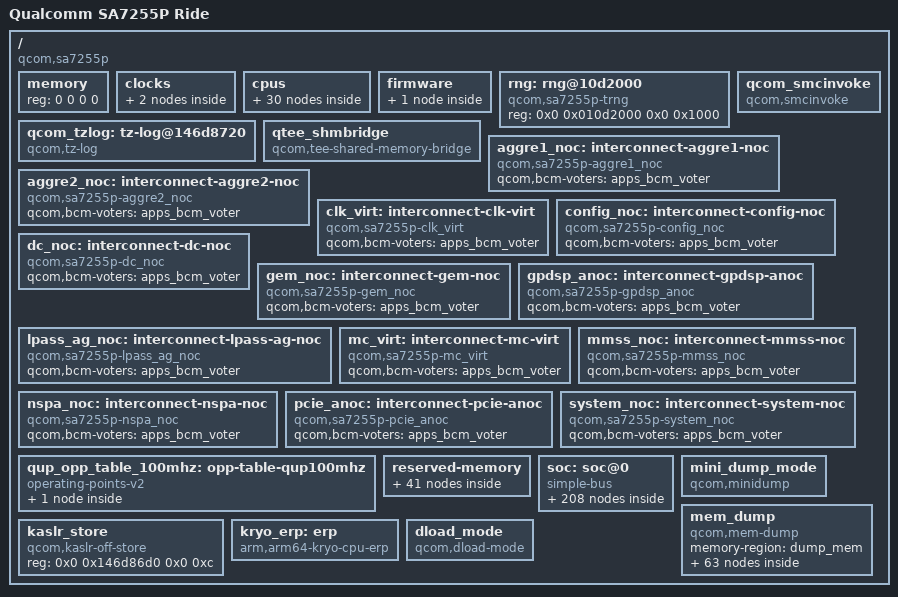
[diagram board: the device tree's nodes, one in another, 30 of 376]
// SPDX-License-Identifier: BSD-3-Clause
/*
 * Copyright (c) 2024 Qualcomm Innovation Center, Inc. All rights reserved.
 */

#include <dt-bindings/interrupt-controller/arm-gic.h>
#include <dt-bindings/clock/qcom,rpmh.h>
#include <dt-bindings/clock/qcom,camcc-sa8775p.h>
#include <dt-bindings/clock/qcom,sa7255p-dispcc.h>
#include <dt-bindings/clock/qcom,sa7255p-gcc.h>
#include <dt-bindings/clock/qcom,sa8775p-gpucc.h>
#include <dt-bindings/clock/qcom,videocc-sa8775p.h>
#include <dt-bindings/interconnect/qcom,sa7255p-rpmh.h>
#include <dt-bindings/interconnect/qcom,icc.h>
#include <dt-bindings/power/qcom-rpmpd.h>
#include <dt-bindings/soc/qcom,rpmh-rsc.h>
#include <oot-dt-bindings/qcom-ipcc.h>

/ {
	model = "Qualcomm SA7255P Ride";
	compatible = "qcom,sa7255p";
	interrupt-parent = <&intc>;

	#address-cells = <2>;
	#size-cells = <2>;

	memory { device_type = "memory"; reg = <0 0 0 0>; };

	clocks {
		xo_board_clk: xo-board-clk {
			compatible = "fixed-clock";
			#clock-cells = <0>;
		};

		sleep_clk: sleep-clk {
			compatible = "fixed-clock";
			#clock-cells = <0>;
		};
	};

	cpus {
		#address-cells = <2>;
		#size-cells = <0>;

		CPU0: cpu@0 {
			device_type = "cpu";
			compatible = "qcom,kryo";
			reg = <0x0 0x0>;
			enable-method = "psci";
			next-level-cache = <&L2_0>;
			L2_0: l2-cache {
			      compatible = "arm,arch-cache";
			      cache-level = <2>;
			      next-level-cache = <&L3_0>;

				L3_0: l3-cache {
				      compatible = "arm,arch-cache";
				      cache-level = <3>;
				};
			};
		};

		CPU1: cpu@100 {
			device_type = "cpu";
			compatible = "qcom,kryo";
			reg = <0x0 0x100>;
			enable-method = "psci";
			next-level-cache = <&L2_1>;
			L2_1: l2-cache {
			      compatible = "arm,arch-cache";
			      cache-level = <2>;
			      next-level-cache = <&L3_0>;
			};
		};

		CPU2: cpu@200 {
			device_type = "cpu";
			compatible = "qcom,kryo";
			reg = <0x0 0x200>;
			enable-method = "psci";
			next-level-cache = <&L2_2>;
			L2_2: l2-cache {
			      compatible = "arm,arch-cache";
			      cache-level = <2>;
			      next-level-cache = <&L3_0>;
			};
		};

		CPU3: cpu@300 {
			device_type = "cpu";
			compatible = "qcom,kryo";
			reg = <0x0 0x300>;
			enable-method = "psci";
			next-level-cache = <&L2_3>;
			L2_3: l2-cache {
			      compatible = "arm,arch-cache";
			      cache-level = <2>;
			      next-level-cache = <&L3_0>;
			};
		};

		CPU4: cpu@10000 {
			device_type = "cpu";
			compatible = "qcom,kryo";
			reg = <0x0 0x10000>;
			enable-method = "psci";
			next-level-cache = <&L2_4>;
			L2_4: l2-cache {
			      compatible = "arm,arch-cache";
			      cache-level = <2>;
			      next-level-cache = <&L3_1>;
				L3_1: l3-cache {
				      compatible = "arm,arch-cache";
				      cache-level = <3>;
				};
			};
		};

		CPU5: cpu@10100 {
			device_type = "cpu";
			compatible = "qcom,kryo";
			reg = <0x0 0x10100>;
			enable-method = "psci";
			next-level-cache = <&L2_5>;
			L2_5: l2-cache {
			      compatible = "arm,arch-cache";
			      cache-level = <2>;
			      next-level-cache = <&L3_1>;
			};
		};

		CPU6: cpu@10200 {
			device_type = "cpu";
			compatible = "qcom,kryo";
			reg = <0x0 0x10200>;
			enable-method = "psci";
			next-level-cache = <&L2_6>;
			L2_6: l2-cache {
			      compatible = "arm,arch-cache";
			      cache-level = <2>;
			      next-level-cache = <&L3_1>;
			};
		};

		CPU7: cpu@10300 {
			device_type = "cpu";
			compatible = "qcom,kryo";
			reg = <0x0 0x10300>;
			enable-method = "psci";
			next-level-cache = <&L2_7>;
			L2_7: l2-cache {
			      compatible = "arm,arch-cache";
			      cache-level = <2>;
			      next-level-cache = <&L3_1>;
			};
		};

		cpu-map {
			cluster0 {
				core0 {
					cpu = <&CPU0>;
				};

				core1 {
					cpu = <&CPU1>;
				};
			};

			cluster1 {
				core0 {
					cpu = <&CPU2>;
				};

				core1 {
					cpu = <&CPU3>;
				};
			};

			cluster2 {
				core0 {
					cpu = <&CPU4>;
				};

				core1 {
					cpu = <&CPU5>;
				};

				core2 {
					cpu = <&CPU6>;
				};

				core3 {
					cpu = <&CPU7>;
				};
			};
		};
	};

	firmware {
		qcom_scm {
			compatible = "qcom,scm";
			qcom,dload-mode = <&tcsr 0x13000>;
		};
	};

	rng: rng@10d2000 {
		compatible = "qcom,sa7255p-trng", "qcom,trng";
		reg = <0x0 0x010d2000 0x0 0x1000>;
	};

	qcom_tzlog: tz-log@146d8720 {
		compatible = "qcom,tz-log";
		reg = <0x0 0x146d8720 0x0 0x3000>;
		qcom,hyplog-enabled;
		hyplog-address-offset = <0x410>;
		hyplog-size-offset = <0x414>;
	};

	qtee_shmbridge {
		compatible = "qcom,tee-shared-memory-bridge";
		qcom,support-hypervisor;
		memory-region = <&cma>;
	};

	qcom_smcinvoke {
		compatible = "qcom,smcinvoke";
	};

	aggre1_noc: interconnect-aggre1-noc {
		compatible = "qcom,sa7255p-aggre1_noc";
		#interconnect-cells = <2>;
		qcom,bcm-voters = <&apps_bcm_voter>;
	};

	aggre2_noc: interconnect-aggre2-noc {
		compatible = "qcom,sa7255p-aggre2_noc";
		#interconnect-cells = <2>;
		qcom,bcm-voters = <&apps_bcm_voter>;
	};

	clk_virt: interconnect-clk-virt {
		compatible = "qcom,sa7255p-clk_virt";
		#interconnect-cells = <2>;
		qcom,bcm-voters = <&apps_bcm_voter>;
	};

	config_noc: interconnect-config-noc {
		compatible = "qcom,sa7255p-config_noc";
		#interconnect-cells = <2>;
		qcom,bcm-voters = <&apps_bcm_voter>;
	};

	dc_noc: interconnect-dc-noc {
		compatible = "qcom,sa7255p-dc_noc";
		#interconnect-cells = <2>;
		qcom,bcm-voters = <&apps_bcm_voter>;
	};

	gem_noc: interconnect-gem-noc {
		compatible = "qcom,sa7255p-gem_noc";
		#interconnect-cells = <2>;
		qcom,bcm-voters = <&apps_bcm_voter>;
	};

	gpdsp_anoc: interconnect-gpdsp-anoc {
		compatible = "qcom,sa7255p-gpdsp_anoc";
		#interconnect-cells = <2>;
		qcom,bcm-voters = <&apps_bcm_voter>;
	};

	lpass_ag_noc: interconnect-lpass-ag-noc {
		compatible = "qcom,sa7255p-lpass_ag_noc";
		#interconnect-cells = <2>;
		qcom,bcm-voters = <&apps_bcm_voter>;
	};

	mc_virt: interconnect-mc-virt {
		compatible = "qcom,sa7255p-mc_virt";
		#interconnect-cells = <2>;
		qcom,bcm-voters = <&apps_bcm_voter>;
	};

	mmss_noc: interconnect-mmss-noc {
		compatible = "qcom,sa7255p-mmss_noc";
		#interconnect-cells = <2>;
		qcom,bcm-voters = <&apps_bcm_voter>;
	};

	nspa_noc: interconnect-nspa-noc {
		compatible = "qcom,sa7255p-nspa_noc";
		#interconnect-cells = <2>;
		qcom,bcm-voters = <&apps_bcm_voter>;
	};

	pcie_anoc: interconnect-pcie-anoc {
		compatible = "qcom,sa7255p-pcie_anoc";
		#interconnect-cells = <2>;
		qcom,bcm-voters = <&apps_bcm_voter>;
	};

	system_noc: interconnect-system-noc {
		compatible = "qcom,sa7255p-system_noc";
		#interconnect-cells = <2>;
		qcom,bcm-voters = <&apps_bcm_voter>;
	};

	qup_opp_table_100mhz: opp-table-qup100mhz {
		compatible = "operating-points-v2";

		opp-100000000 {
			opp-hz = /bits/ 64 <100000000>;
			required-opps = <&rpmhpd_opp_svs_l1>;
		};
	};

	reserved-memory {
		#address-cells = <2>;
		#size-cells = <2>;
		ranges;

		sail_ss_mem: sail_ss_region@80000000 {
			no-map;
			reg = <0x0 0x80000000 0x0 0x10000000>;
		};

		hyp_mem: hyp_region@90000000 {
			no-map;
			reg = <0x0 0x90000000 0x0 0x600000>;
		};

		xbl_boot_mem: xbl_boot_region@90700000 {
			no-map;
			reg = <0x0 0x90700000 0x0 0x100000>;
		};

		aop_image_mem: aop_image_region@90800000 {
			no-map;
			reg = <0x0 0x90800000 0x0 0x60000>;
		};

		aop_cmd_db_mem: aop_cmd_db_region@90860000 {
			compatible = "qcom,cmd-db";
			no-map;
			reg = <0x0 0x90860000 0x0 0x20000>;
		};

		uefi_xbl_logs_mem: uefi_xbl_logs_region@908b0000 {
			no-map;
			reg = <0x0 0x908b0000 0x0 0x10000>;
		};

		ddr_training_cksum_data_mem: ddr_training_cksum_data_region@908c0000 {
			no-map;
			reg = <0x0 0x908c0000 0x0 0x1000>;
		};

		reserved_mem: reserved_region@908f0000 {
			no-map;
			reg = <0x0 0x908f0000 0x0 0xe000>;
		};

		secdata_apss_mem: secdata_apss_region@908fe000 {
			no-map;
			reg = <0x0 0x908fe000 0x0 0x2000>;
		};

		secboot_emulation_mem: secboot_emulation_region@908fe000 {
			no-map;
			reg = <0x0 0x908fe000 0x0 0x1000>;
		};

		smem_mem: smem@90900000 {
			compatible = "qcom,smem";
			reg = <0x0 0x90900000 0x0 0x200000>;
			no-map;
			hwlocks = <&tcsr_mutex 3>;
		};


		tz_sail_mailbox_mem: tz_sail_mailbox_region@90c00000 {
			no-map;
			reg = <0x0 0x90c00000 0x0 0x100000>;
		};

		hlos_sail_mailbox_mem: hlos_sail_mailbox_region@90d00000 {
			no-map;
			reg = <0x0 0x90d00000 0x0 0x100000>;
		};

		sail_ota_mem: sail_ota_region@90e00000 {
			no-map;
			reg = <0x0 0x90e00000 0x0 0x300000>;
		};

		aoss_backup_mem: aoss_backup_region@91b00000 {
			no-map;
			reg = <0x0 0x91b00000 0x0 0x40000>;
		};

		cpucp_backup_mem: cpucp_backup_region@91b40000 {
			no-map;
			reg = <0x0 0x91b40000 0x0 0x40000>;
		};

		tz_config_backup_mem: tz_config_backup_region@91b80000 {
			no-map;
			reg = <0x0 0x91b80000 0x0 0x10000>;
		};

		ddr_training_data_mem: ddr_training_data_region@91b90000 {
			no-map;
			reg = <0x0 0x91b90000 0x0 0x10000>;
		};

		cdt_data_backup_mem: cdt_data_backup_region@91ba0000 {
			no-map;
			reg = <0x0 0x91ba0000 0x0 0x1000>;
		};

		lpass_machine_learning_mem: lpass_machine_learning_region@93b00000 {
			no-map;
			reg = <0x0 0x93b00000 0x0 0xf00000>;
		};

		adsp_rpc_remote_heap_mem: adsp_rpc_remote_heap_region@94a00000 {
			no-map;
			reg = <0x0 0x94a00000 0x0 0x800000>;
		};

		camera_mem: camera_region@95200000 {
			no-map;
			reg = <0x0 0x95200000 0x0 0x500000>;
		};

		mproc_umdpil_mem: mproc_umdpil_region@95700000 {
			no-map;
			reg = <0x0 0x95700000 0x0 0x500000>;
		};

		adsp_mem: adsp_region@95c00000 {
			no-map;
			reg = <0x0 0x95c00000 0x0 0x1e00000>;
		};

		gpdsp_mem: gpdsp_region@97b00000 {
			no-map;
			reg = <0x0 0x97b00000 0x0 0x1e00000>;
		};

		cdsp_mem: cdsp_region@99980000 {
			no-map;
			reg = <0x0 0x99980000 0x0 0x1e00000>;
		};

		gpu_microcode_mem: gpu_microcode_region@9b780000 {
			no-map;
			reg = <0x0 0x9b780000 0x0 0x2000>;
		};

		cvp_mem: cvp_region@9b782000 {
			no-map;
			reg = <0x0 0x9b782000 0x0 0x700000>;
		};

		video_mem: video_region@9be82000 {
			no-map;
			reg = <0x0 0x9be82000 0x0 0x700000>;
		};

		hyp_logging_mem: hyp_logging_region@beb00000 {
			no-map;
			reg = <0x0 0xbeb00000 0x0 0x2000000>;
		};

		heap_mem: heap_region@c0b00000 {
			no-map;
			reg = <0x0 0xc0b00000 0x0 0x400000>;
		};

		tags_mem: tags_region@d0100000 {
			no-map;
			reg = <0x0 0xd0100000 0x0 0x800000>;
		};

		pimem_vault_1_mem: pimem_vault_1_region@d0900000 {
			no-map;
			reg = <0x0 0xd0900000 0x0 0xa00000>;
		};

		qtee_mem: qtee_region@d1300000 {
			no-map;
			reg = <0x0 0xd1300000 0x0 0x500000>;
		};

		deep_sleep_back_up_mem: deep_sleep_back_up_region@d1800000 {
			no-map;
			reg = <0x0 0xd1800000 0x0 0x100000>;
		};

		trusted_apps_mem: trusted_apps_region@d1900000 {
			no-map;
			reg = <0x0 0xd1900000 0x0 0x1900000>;
		};

		pimem_vault_2_mem: pimem_vault_2_region@d3200000 {
			no-map;
			reg = <0x0 0xd3200000 0x0 0x100000>;
		};

		tz_stat_mem: tz_stat_region@db100000 {
			no-map;
			reg = <0x0 0xdb100000 0x0 0x100000>;
		};

		cpucp_fw_mem: cpucp_fw_region@db200000 {
			no-map;
			reg = <0x0 0xdb200000 0x0 0x100000>;
		};

		/* global autoconfigured region for contiguous allocations */
		cma: linux,cma {
			compatible = "shared-dma-pool";
			alloc-ranges = <0x0 0x00000000 0x0 0xffffffff>;
			reusable;
			alignment = <0x0 0x400000>;
			size = <0x0 0x2000000>;
			linux,cma-default;
		};

		dump_mem: mem_dump_region {
			alloc-ranges = <0x0 0x00000000 0x0 0xffffffff>;
			compatible = "shared-dma-pool";
			reusable;
			size = <0x0 0x3000000>;
		};
	};

	soc: soc@0 {
		#address-cells = <2>;
		#size-cells = <2>;
		ranges = <0 0 0 0 0x10 0>;
		compatible = "simple-bus";

		gcc: clock-controller@100000 {
			compatible = "qcom,sa7255p-gcc";
			reg = <0x0 0x00100000 0x0 0xc7018>;
			#clock-cells = <1>;
			#reset-cells = <1>;
			#power-domain-cells = <1>;
			clocks = <&rpmhcc RPMH_CXO_CLK>,
				 <&sleep_clk>,
				 <0>,
				 <0>,
				 <0>,
				 <&usb_0_qmpphy>,
				 <0>,
				 <0>,
				 <0>,
				 <0>;
			power-domains = <&rpmhpd SA7255P_CX>;
		};

		gpucc: clock-controller@3d90000 {
			compatible = "qcom,sa7255p-gpucc";
			reg = <0x0 0x03d90000 0x0 0xa000>;
			clocks = <&rpmhcc RPMH_CXO_CLK>,
				 <&gcc GCC_GPU_GPLL0_CLK_SRC>,
				 <&gcc GCC_GPU_GPLL0_DIV_CLK_SRC>;
			clock-names = "bi_tcxo",
				      "gcc_gpu_gpll0_clk_src",
				      "gcc_gpu_gpll0_div_clk_src";
			#clock-cells = <1>;
			#reset-cells = <1>;
			#power-domain-cells = <1>;
		};

		videocc: clock-controller@abf0000 {
			compatible = "qcom,sa7255p-videocc";
			reg = <0x0 0xabf0000 0x0 0x10000>;
			clocks = <&gcc GCC_VIDEO_AHB_CLK>,
				 <&rpmhcc RPMH_CXO_CLK>,
				 <&rpmhcc RPMH_CXO_CLK_A>,
				 <&sleep_clk>;
			power-domains = <&rpmhpd SA7255P_MMCX>;
			required-opps = <&rpmhpd_opp_nom>;
			#clock-cells = <1>;
			#reset-cells = <1>;
			#power-domain-cells = <1>;
		};

		camcc: clock-controller@ade0000 {
			compatible = "qcom,sa7255p-camcc";
			reg = <0x0 0xade0000 0x0 0x20000>;
			clocks = <&gcc GCC_CAMERA_AHB_CLK>,
				 <&rpmhcc RPMH_CXO_CLK>,
				 <&rpmhcc RPMH_CXO_CLK_A>,
				 <&sleep_clk>;
			power-domains = <&rpmhpd SA7255P_MMCX>;
			required-opps = <&rpmhpd_opp_nom>;
			#clock-cells = <1>;
			#reset-cells = <1>;
			#power-domain-cells = <1>;
		};

		dispcc: clock-controller@af00000 {
			compatible = "qcom,sa7255p-dispcc";
			reg = <0x0 0xaf00000 0x0 0x20000>;
			clocks = <&gcc GCC_DISP_AHB_CLK>,
				 <&rpmhcc RPMH_CXO_CLK>,
				 <&rpmhcc RPMH_CXO_CLK_A>,
				 <&sleep_clk>,
				 <0>,
				 <0>,
				 <0>,
				 <0>,
				 <0>,
				 <0>,
				 <0>,
				 <0>;
			power-domains = <&rpmhpd SA7255P_MMCX>;
			required-opps = <&rpmhpd_opp_nom>;
			#clock-cells = <1>;
			#reset-cells = <1>;
			#power-domain-cells = <1>;
		};

		dummy_proxy_votes: dummy-proxy-votes {
			compatible = "qcom,sa7255p-dummy";
			power-domains = <&rpmhpd SA7255P_NSP0>,
					<&rpmhpd SA7255P_NSP1>;
		};

		qupv3_id_0: geniqup@9c0000 {
			compatible = "qcom,geni-se-qup";
			reg = <0x0 0x9c0000 0x0 0x2000>;
			#address-cells = <2>;
			#size-cells = <2>;
			ranges;
			clock-names = "m-ahb", "s-ahb";
			clocks = <&gcc GCC_QUPV3_WRAP_0_M_AHB_CLK>,
				<&gcc GCC_QUPV3_WRAP_0_S_AHB_CLK>;
			iommus = <&apps_smmu 0x403 0x0>;
			status = "disabled";

			i2c0: i2c@980000 {
				compatible = "qcom,geni-i2c";
				reg = <0x0 0x980000 0x0 0x4000>;
				#address-cells = <1>;
				#size-cells = <0>;
				interrupts = <GIC_SPI 550 IRQ_TYPE_LEVEL_HIGH>;
				clocks = <&gcc GCC_QUPV3_WRAP0_S0_CLK>;
				clock-names = "se";
				interconnects = <&clk_virt MASTER_QUP_CORE_0 QCOM_ICC_TAG_ALWAYS
						 &clk_virt SLAVE_QUP_CORE_0 QCOM_ICC_TAG_ALWAYS>,
						<&gem_noc MASTER_APPSS_PROC QCOM_ICC_TAG_ALWAYS
						 &config_noc SLAVE_QUP_0 QCOM_ICC_TAG_ALWAYS>,
						<&aggre2_noc MASTER_QUP_0 QCOM_ICC_TAG_ALWAYS
						 &mc_virt SLAVE_EBI1 QCOM_ICC_TAG_ALWAYS>;
				interconnect-names = "qup-core",
						     "qup-config",
						     "qup-memory";
				power-domains = <&rpmhpd SA7255P_CX>;
				status = "disabled";
			};

			i2c1: i2c@984000 {
				compatible = "qcom,geni-i2c";
				reg = <0x0 0x984000 0x0 0x4000>;
				#address-cells = <1>;
				#size-cells = <0>;
				interrupts = <GIC_SPI 551 IRQ_TYPE_LEVEL_HIGH>;
				clocks = <&gcc GCC_QUPV3_WRAP0_S1_CLK>;
				clock-names = "se";
				interconnects = <&clk_virt MASTER_QUP_CORE_0 QCOM_ICC_TAG_ALWAYS
						 &clk_virt SLAVE_QUP_CORE_0 QCOM_ICC_TAG_ALWAYS>,
						<&gem_noc MASTER_APPSS_PROC QCOM_ICC_TAG_ALWAYS
						 &config_noc SLAVE_QUP_0 QCOM_ICC_TAG_ALWAYS>,
						<&aggre2_noc MASTER_QUP_0 QCOM_ICC_TAG_ALWAYS
						 &mc_virt SLAVE_EBI1 QCOM_ICC_TAG_ALWAYS>;
				interconnect-names = "qup-core",
						     "qup-config",
						     "qup-memory";
				power-domains = <&rpmhpd SA7255P_CX>;
				status = "disabled";
			};

			i2c2: i2c@988000 {
				compatible = "qcom,geni-i2c";
				reg = <0x0 0x988000 0x0 0x4000>;
				#address-cells = <1>;
				#size-cells = <0>;
				interrupts = <GIC_SPI 529 IRQ_TYPE_LEVEL_HIGH>;
				clocks = <&gcc GCC_QUPV3_WRAP0_S2_CLK>;
				clock-names = "se";
				interconnects = <&clk_virt MASTER_QUP_CORE_0 QCOM_ICC_TAG_ALWAYS
						 &clk_virt SLAVE_QUP_CORE_0 QCOM_ICC_TAG_ALWAYS>,
						<&gem_noc MASTER_APPSS_PROC QCOM_ICC_TAG_ALWAYS
						 &config_noc SLAVE_QUP_0 QCOM_ICC_TAG_ALWAYS>,
						<&aggre2_noc MASTER_QUP_0 QCOM_ICC_TAG_ALWAYS
						 &mc_virt SLAVE_EBI1 QCOM_ICC_TAG_ALWAYS>;
				interconnect-names = "qup-core",
						     "qup-config",
						     "qup-memory";
				power-domains = <&rpmhpd SA7255P_CX>;
				status = "disabled";
			};

			spi2: spi@988000 {
				compatible = "qcom,geni-spi";
				reg = <0x0 0x988000 0x0 0x4000>;
				#address-cells = <1>;
				#size-cells = <0>;
				interrupts = <GIC_SPI 529 IRQ_TYPE_LEVEL_HIGH>;
				clocks = <&gcc GCC_QUPV3_WRAP0_S2_CLK>;
				clock-names = "se";
				interconnects = <&clk_virt MASTER_QUP_CORE_0 QCOM_ICC_TAG_ALWAYS
						 &clk_virt SLAVE_QUP_CORE_0 QCOM_ICC_TAG_ALWAYS>,
						<&gem_noc MASTER_APPSS_PROC QCOM_ICC_TAG_ALWAYS
						 &config_noc SLAVE_QUP_0 QCOM_ICC_TAG_ALWAYS>,
						<&aggre2_noc MASTER_QUP_0 QCOM_ICC_TAG_ALWAYS
						 &mc_virt SLAVE_EBI1 QCOM_ICC_TAG_ALWAYS>;
				interconnect-names = "qup-core",
						     "qup-config",
						     "qup-memory";
				power-domains = <&rpmhpd SA7255P_CX>;
				status = "disabled";
			};

			uart2: serial@988000 {
				compatible = "qcom,geni-uart";
				reg = <0x0 0x988000 0x0 0x4000>;
				interrupts = <GIC_SPI 529 IRQ_TYPE_LEVEL_HIGH>;
				clocks = <&gcc GCC_QUPV3_WRAP0_S2_CLK>;
				clock-names = "se";
				interconnects = <&clk_virt MASTER_QUP_CORE_0 QCOM_ICC_TAG_ALWAYS
						 &clk_virt SLAVE_QUP_CORE_0 QCOM_ICC_TAG_ALWAYS>,
						<&gem_noc MASTER_APPSS_PROC QCOM_ICC_TAG_ALWAYS
						 &config_noc SLAVE_QUP_0 QCOM_ICC_TAG_ALWAYS>;
				interconnect-names = "qup-core", "qup-config";
				power-domains = <&rpmhpd SA7255P_CX>;
				status = "disabled";
			};

			i2c3: i2c@98c000 {
				compatible = "qcom,geni-i2c";
				reg = <0x0 0x98c000 0x0 0x4000>;
				#address-cells = <1>;
				#size-cells = <0>;
				interrupts = <GIC_SPI 530 IRQ_TYPE_LEVEL_HIGH>;
				clocks = <&gcc GCC_QUPV3_WRAP0_S3_CLK>;
				clock-names = "se";
				interconnects = <&clk_virt MASTER_QUP_CORE_0 QCOM_ICC_TAG_ALWAYS
						 &clk_virt SLAVE_QUP_CORE_0 QCOM_ICC_TAG_ALWAYS>,
						<&gem_noc MASTER_APPSS_PROC QCOM_ICC_TAG_ALWAYS
						 &config_noc SLAVE_QUP_0 QCOM_ICC_TAG_ALWAYS>,
						<&aggre2_noc MASTER_QUP_0 QCOM_ICC_TAG_ALWAYS
						 &mc_virt SLAVE_EBI1 QCOM_ICC_TAG_ALWAYS>;
				interconnect-names = "qup-core",
						     "qup-config",
						     "qup-memory";
				power-domains = <&rpmhpd SA7255P_CX>;
				status = "disabled";
			};

			spi3: spi@98c000 {
				compatible = "qcom,geni-spi";
				reg = <0x0 0x98c000 0x0 0x4000>;
				#address-cells = <1>;
				#size-cells = <0>;
				interrupts = <GIC_SPI 530 IRQ_TYPE_LEVEL_HIGH>;
				clocks = <&gcc GCC_QUPV3_WRAP0_S3_CLK>;
				clock-names = "se";
				interconnects = <&clk_virt MASTER_QUP_CORE_0 QCOM_ICC_TAG_ALWAYS
						 &clk_virt SLAVE_QUP_CORE_0 QCOM_ICC_TAG_ALWAYS>,
						<&gem_noc MASTER_APPSS_PROC QCOM_ICC_TAG_ALWAYS
						 &config_noc SLAVE_QUP_0 QCOM_ICC_TAG_ALWAYS>,
						<&aggre2_noc MASTER_QUP_0 QCOM_ICC_TAG_ALWAYS
						 &mc_virt SLAVE_EBI1 QCOM_ICC_TAG_ALWAYS>;
				interconnect-names = "qup-core",
						     "qup-config",
						     "qup-memory";
				power-domains = <&rpmhpd SA7255P_CX>;
				status = "disabled";
			};

			uart3: serial@98c000 {
				compatible = "qcom,geni-uart";
				reg = <0x0 0x98c000 0x0 0x4000>;
				interrupts = <GIC_SPI 530 IRQ_TYPE_LEVEL_HIGH>;
				clocks = <&gcc GCC_QUPV3_WRAP0_S3_CLK>;
				clock-names = "se";
				interconnects = <&clk_virt MASTER_QUP_CORE_0 QCOM_ICC_TAG_ALWAYS
						 &clk_virt SLAVE_QUP_CORE_0 QCOM_ICC_TAG_ALWAYS>,
						<&gem_noc MASTER_APPSS_PROC QCOM_ICC_TAG_ALWAYS
						 &config_noc SLAVE_QUP_0 QCOM_ICC_TAG_ALWAYS>;
				interconnect-names = "qup-core", "qup-config";
				power-domains = <&rpmhpd SA7255P_CX>;
				status = "disabled";
			};

			i2c4: i2c@990000 {
				compatible = "qcom,geni-i2c";
				reg = <0x0 0x990000 0x0 0x4000>;
				#address-cells = <1>;
				#size-cells = <0>;
				interrupts = <GIC_SPI 531 IRQ_TYPE_LEVEL_HIGH>;
				clocks = <&gcc GCC_QUPV3_WRAP0_S4_CLK>;
				clock-names = "se";
				interconnects = <&clk_virt MASTER_QUP_CORE_0 QCOM_ICC_TAG_ALWAYS
						 &clk_virt SLAVE_QUP_CORE_0 QCOM_ICC_TAG_ALWAYS>,
						<&gem_noc MASTER_APPSS_PROC QCOM_ICC_TAG_ALWAYS
						 &config_noc SLAVE_QUP_0 QCOM_ICC_TAG_ALWAYS>,
						<&aggre2_noc MASTER_QUP_0 QCOM_ICC_TAG_ALWAYS
						 &mc_virt SLAVE_EBI1 QCOM_ICC_TAG_ALWAYS>;
				interconnect-names = "qup-core",
						     "qup-config",
						     "qup-memory";
				power-domains = <&rpmhpd SA7255P_CX>;
				status = "disabled";
			};

			spi4: spi@990000 {
				compatible = "qcom,geni-spi";
				reg = <0x0 0x990000 0x0 0x4000>;
				#address-cells = <1>;
				#size-cells = <0>;
				interrupts = <GIC_SPI 531 IRQ_TYPE_LEVEL_HIGH>;
				clocks = <&gcc GCC_QUPV3_WRAP0_S4_CLK>;
				clock-names = "se";
				interconnects = <&clk_virt MASTER_QUP_CORE_0 QCOM_ICC_TAG_ALWAYS
						 &clk_virt SLAVE_QUP_CORE_0 QCOM_ICC_TAG_ALWAYS>,
						<&gem_noc MASTER_APPSS_PROC QCOM_ICC_TAG_ALWAYS
						 &config_noc SLAVE_QUP_0 QCOM_ICC_TAG_ALWAYS>,
						<&aggre2_noc MASTER_QUP_0 QCOM_ICC_TAG_ALWAYS
						 &mc_virt SLAVE_EBI1 QCOM_ICC_TAG_ALWAYS>;
				interconnect-names = "qup-core",
						     "qup-config",
						     "qup-memory";
				power-domains = <&rpmhpd SA7255P_CX>;
				status = "disabled";
			};

			i2c5: i2c@994000 {
				compatible = "qcom,geni-i2c";
				reg = <0x0 0x994000 0x0 0x4000>;
				#address-cells = <1>;
				#size-cells = <0>;
				interrupts = <GIC_SPI 535 IRQ_TYPE_LEVEL_HIGH>;
				clocks = <&gcc GCC_QUPV3_WRAP0_S5_CLK>;
				clock-names = "se";
				interconnects = <&clk_virt MASTER_QUP_CORE_0 QCOM_ICC_TAG_ALWAYS
						 &clk_virt SLAVE_QUP_CORE_0 QCOM_ICC_TAG_ALWAYS>,
						<&gem_noc MASTER_APPSS_PROC QCOM_ICC_TAG_ALWAYS
						 &config_noc SLAVE_QUP_0 QCOM_ICC_TAG_ALWAYS>,
						<&aggre2_noc MASTER_QUP_0 QCOM_ICC_TAG_ALWAYS
						 &mc_virt SLAVE_EBI1 QCOM_ICC_TAG_ALWAYS>;
				interconnect-names = "qup-core",
						     "qup-config",
						     "qup-memory";
				power-domains = <&rpmhpd SA7255P_CX>;
				status = "disabled";
			};

			spi5: spi@994000 {
				compatible = "qcom,geni-spi";
				reg = <0x0 0x994000 0x0 0x4000>;
				#address-cells = <1>;
				#size-cells = <0>;
				interrupts = <GIC_SPI 535 IRQ_TYPE_LEVEL_HIGH>;
				clocks = <&gcc GCC_QUPV3_WRAP0_S5_CLK>;
				clock-names = "se";
				interconnects = <&clk_virt MASTER_QUP_CORE_0 QCOM_ICC_TAG_ALWAYS
						 &clk_virt SLAVE_QUP_CORE_0 QCOM_ICC_TAG_ALWAYS>,
						<&gem_noc MASTER_APPSS_PROC QCOM_ICC_TAG_ALWAYS
						 &config_noc SLAVE_QUP_0 QCOM_ICC_TAG_ALWAYS>,
						<&aggre2_noc MASTER_QUP_0 QCOM_ICC_TAG_ALWAYS
						 &mc_virt SLAVE_EBI1 QCOM_ICC_TAG_ALWAYS>;
				interconnect-names = "qup-core",
						     "qup-config",
						     "qup-memory";
				power-domains = <&rpmhpd SA7255P_CX>;
				status = "disabled";
			};

			uart5: serial@994000 {
				compatible = "qcom,geni-uart";
				reg = <0x0 0x994000 0x0 0x4000>;
				interrupts = <GIC_SPI 535 IRQ_TYPE_LEVEL_HIGH>;
				clocks = <&gcc GCC_QUPV3_WRAP0_S5_CLK>;
				clock-names = "se";
				interconnects = <&clk_virt MASTER_QUP_CORE_0 QCOM_ICC_TAG_ALWAYS
						 &clk_virt SLAVE_QUP_CORE_0 QCOM_ICC_TAG_ALWAYS>,
						<&gem_noc MASTER_APPSS_PROC QCOM_ICC_TAG_ALWAYS
						 &config_noc SLAVE_QUP_0 QCOM_ICC_TAG_ALWAYS>;
				interconnect-names = "qup-core", "qup-config";
				power-domains = <&rpmhpd SA7255P_CX>;
				status = "disabled";
			};

			i2c6: i2c@998000 {
				compatible = "qcom,geni-i2c";
				reg = <0x0 0x998000 0x0 0x4000>;
				#address-cells = <1>;
				#size-cells = <0>;
				interrupts = <GIC_SPI 536 IRQ_TYPE_LEVEL_HIGH>;
				clocks = <&gcc GCC_QUPV3_WRAP0_S6_CLK>;
				clock-names = "se";
				interconnects = <&clk_virt MASTER_QUP_CORE_0 QCOM_ICC_TAG_ALWAYS
						 &clk_virt SLAVE_QUP_CORE_0 QCOM_ICC_TAG_ALWAYS>,
						<&gem_noc MASTER_APPSS_PROC QCOM_ICC_TAG_ALWAYS
						 &config_noc SLAVE_QUP_0 QCOM_ICC_TAG_ALWAYS>,
						<&aggre2_noc MASTER_QUP_0 QCOM_ICC_TAG_ALWAYS
						 &mc_virt SLAVE_EBI1 QCOM_ICC_TAG_ALWAYS>;
				interconnect-names = "qup-core",
						     "qup-config",
						     "qup-memory";
				power-domains = <&rpmhpd SA7255P_CX>;
				status = "disabled";
			};

			spi6: spi@998000 {
				compatible = "qcom,geni-spi";
				reg = <0x0 0x998000 0x0 0x4000>;
				#address-cells = <1>;
				#size-cells = <0>;
				interrupts = <GIC_SPI 536 IRQ_TYPE_LEVEL_HIGH>;
				clocks = <&gcc GCC_QUPV3_WRAP0_S6_CLK>;
				clock-names = "se";
				interconnects = <&clk_virt MASTER_QUP_CORE_0 QCOM_ICC_TAG_ALWAYS
						 &clk_virt SLAVE_QUP_CORE_0 QCOM_ICC_TAG_ALWAYS>,
						<&gem_noc MASTER_APPSS_PROC QCOM_ICC_TAG_ALWAYS
						 &config_noc SLAVE_QUP_0 QCOM_ICC_TAG_ALWAYS>,
						<&aggre2_noc MASTER_QUP_0 QCOM_ICC_TAG_ALWAYS
						 &mc_virt SLAVE_EBI1 QCOM_ICC_TAG_ALWAYS>;
				interconnect-names = "qup-core",
						     "qup-config",
						     "qup-memory";
				power-domains = <&rpmhpd SA7255P_CX>;
				status = "disabled";
			};

			uart7: serial@99c000 {
				compatible = "qcom,geni-uart";
				reg = <0x0 0x0099c000 0x0 0x4000>;
				interrupts = <GIC_SPI 126 IRQ_TYPE_LEVEL_HIGH>;
				clock-names = "se";
				clocks = <&gcc GCC_QUPV3_WRAP0_S7_CLK>;
				interconnect-names = "qup-core", "qup-config";
				interconnects = <&clk_virt MASTER_QUP_CORE_0 0
						 &clk_virt SLAVE_QUP_CORE_0 0>,
						<&gem_noc MASTER_APPSS_PROC 0
						 &config_noc SLAVE_QUP_0 0>;
				power-domains = <&rpmhpd SA7255P_CX>;
				operating-points-v2 = <&qup_opp_table_100mhz>;
				status = "disabled";
			};
		};

		qupv3_id_1: geniqup@ac0000 {
			compatible = "qcom,geni-se-qup";
			reg = <0x0 0x00ac0000 0x0 0x2000>;
			#address-cells = <2>;
			#size-cells = <2>;
			ranges;
			clock-names = "m-ahb", "s-ahb";
			clocks = <&gcc GCC_QUPV3_WRAP_1_M_AHB_CLK>,
				 <&gcc GCC_QUPV3_WRAP_1_S_AHB_CLK>;
			iommus = <&apps_smmu 0x443 0x0>;
			status = "disabled";

			i2c8: i2c@a80000 {
				compatible = "qcom,geni-i2c";
				reg = <0x0 0xa80000 0x0 0x4000>;
				#address-cells = <1>;
				#size-cells = <0>;
				interrupts = <GIC_SPI 353 IRQ_TYPE_LEVEL_HIGH>;
				clocks = <&gcc GCC_QUPV3_WRAP1_S0_CLK>;
				clock-names = "se";
				interconnects = <&clk_virt MASTER_QUP_CORE_1 QCOM_ICC_TAG_ALWAYS
						 &clk_virt SLAVE_QUP_CORE_1 QCOM_ICC_TAG_ALWAYS>,
						<&gem_noc MASTER_APPSS_PROC QCOM_ICC_TAG_ALWAYS
						 &config_noc SLAVE_QUP_1 QCOM_ICC_TAG_ALWAYS>,
						<&aggre2_noc MASTER_QUP_1 QCOM_ICC_TAG_ALWAYS
						 &mc_virt SLAVE_EBI1 QCOM_ICC_TAG_ALWAYS>;
				interconnect-names = "qup-core",
						     "qup-config",
						     "qup-memory";
				power-domains = <&rpmhpd SA7255P_CX>;
				status = "disabled";
			};

			i2c9: i2c@a84000 {
				compatible = "qcom,geni-i2c";
				reg = <0x0 0xa84000 0x0 0x4000>;
				#address-cells = <1>;
				#size-cells = <0>;
				interrupts = <GIC_SPI 354 IRQ_TYPE_LEVEL_HIGH>;
				clocks = <&gcc GCC_QUPV3_WRAP1_S1_CLK>;
				clock-names = "se";
				interconnects = <&clk_virt MASTER_QUP_CORE_1 QCOM_ICC_TAG_ALWAYS
						 &clk_virt SLAVE_QUP_CORE_1 QCOM_ICC_TAG_ALWAYS>,
						<&gem_noc MASTER_APPSS_PROC QCOM_ICC_TAG_ALWAYS
						 &config_noc SLAVE_QUP_1 QCOM_ICC_TAG_ALWAYS>,
						<&aggre2_noc MASTER_QUP_1 QCOM_ICC_TAG_ALWAYS
						 &mc_virt SLAVE_EBI1 QCOM_ICC_TAG_ALWAYS>;
				interconnect-names = "qup-core",
						     "qup-config",
						     "qup-memory";
				power-domains = <&rpmhpd SA7255P_CX>;
				status = "disabled";
			};

			i2c10: i2c@a88000 {
				compatible = "qcom,geni-i2c";
				reg = <0x0 0xa88000 0x0 0x4000>;
				#address-cells = <1>;
				#size-cells = <0>;
				interrupts = <GIC_SPI 355 IRQ_TYPE_LEVEL_HIGH>;
				clocks = <&gcc GCC_QUPV3_WRAP1_S2_CLK>;
				clock-names = "se";
				interconnects = <&clk_virt MASTER_QUP_CORE_1 QCOM_ICC_TAG_ALWAYS
						 &clk_virt SLAVE_QUP_CORE_1 QCOM_ICC_TAG_ALWAYS>,
						<&gem_noc MASTER_APPSS_PROC QCOM_ICC_TAG_ALWAYS
						 &config_noc SLAVE_QUP_1 QCOM_ICC_TAG_ALWAYS>,
						<&aggre2_noc MASTER_QUP_1 QCOM_ICC_TAG_ALWAYS
						 &mc_virt SLAVE_EBI1 QCOM_ICC_TAG_ALWAYS>;
				interconnect-names = "qup-core",
						     "qup-config",
						     "qup-memory";
				power-domains = <&rpmhpd SA7255P_CX>;
				status = "disabled";
			};

			spi10: spi@a88000 {
				compatible = "qcom,geni-spi";
				reg = <0x0 0xa88000 0x0 0x4000>;
				#address-cells = <1>;
				#size-cells = <0>;
				interrupts = <GIC_SPI 355 IRQ_TYPE_LEVEL_HIGH>;
				clocks = <&gcc GCC_QUPV3_WRAP1_S2_CLK>;
				clock-names = "se";
				interconnects = <&clk_virt MASTER_QUP_CORE_1 QCOM_ICC_TAG_ALWAYS
						 &clk_virt SLAVE_QUP_CORE_1 QCOM_ICC_TAG_ALWAYS>,
						<&gem_noc MASTER_APPSS_PROC QCOM_ICC_TAG_ALWAYS
						 &config_noc SLAVE_QUP_1 QCOM_ICC_TAG_ALWAYS>,
						<&aggre2_noc MASTER_QUP_1 QCOM_ICC_TAG_ALWAYS
						 &mc_virt SLAVE_EBI1 QCOM_ICC_TAG_ALWAYS>;
				interconnect-names = "qup-core",
						     "qup-config",
						     "qup-memory";
				power-domains = <&rpmhpd SA7255P_CX>;
				status = "disabled";
			};

			i2c11: i2c@a8c000 {
				compatible = "qcom,geni-i2c";
				reg = <0x0 0xa8c000 0x0 0x4000>;
				#address-cells = <1>;
				#size-cells = <0>;
				interrupts = <GIC_SPI 356 IRQ_TYPE_LEVEL_HIGH>;
				clocks = <&gcc GCC_QUPV3_WRAP1_S3_CLK>;
				clock-names = "se";
				interconnects = <&clk_virt MASTER_QUP_CORE_1 QCOM_ICC_TAG_ALWAYS
						 &clk_virt SLAVE_QUP_CORE_1 QCOM_ICC_TAG_ALWAYS>,
						<&gem_noc MASTER_APPSS_PROC QCOM_ICC_TAG_ALWAYS
						 &config_noc SLAVE_QUP_1 QCOM_ICC_TAG_ALWAYS>,
						<&aggre2_noc MASTER_QUP_1 QCOM_ICC_TAG_ALWAYS
						 &mc_virt SLAVE_EBI1 QCOM_ICC_TAG_ALWAYS>;
				interconnect-names = "qup-core",
						     "qup-config",
						     "qup-memory";
				power-domains = <&rpmhpd SA7255P_CX>;
				status = "disabled";
			};

			uart11: serial@a8c000 {
				compatible = "qcom,geni-uart";
				reg = <0x0 0xa8c000 0x0 0x4000>;
				interrupts = <GIC_SPI 356 IRQ_TYPE_LEVEL_HIGH>;
				clocks = <&gcc GCC_QUPV3_WRAP1_S3_CLK>;
				clock-names = "se";
				interconnects = <&clk_virt MASTER_QUP_CORE_1 QCOM_ICC_TAG_ALWAYS
						 &clk_virt SLAVE_QUP_CORE_1 QCOM_ICC_TAG_ALWAYS>,
						<&gem_noc MASTER_APPSS_PROC QCOM_ICC_TAG_ALWAYS
						 &config_noc SLAVE_QUP_1 QCOM_ICC_TAG_ALWAYS>;
				interconnect-names = "qup-core", "qup-config";
				power-domains = <&rpmhpd SA7255P_CX>;
				status = "disabled";
			};

			i2c12: i2c@a90000 {
				compatible = "qcom,geni-i2c";
				reg = <0x0 0xa90000 0x0 0x4000>;
				#address-cells = <1>;
				#size-cells = <0>;
				interrupts = <GIC_SPI 357 IRQ_TYPE_LEVEL_HIGH>;
				clocks = <&gcc GCC_QUPV3_WRAP1_S4_CLK>;
				clock-names = "se";
				interconnects = <&clk_virt MASTER_QUP_CORE_1 QCOM_ICC_TAG_ALWAYS
						 &clk_virt SLAVE_QUP_CORE_1 QCOM_ICC_TAG_ALWAYS>,
						<&gem_noc MASTER_APPSS_PROC QCOM_ICC_TAG_ALWAYS
						 &config_noc SLAVE_QUP_1 QCOM_ICC_TAG_ALWAYS>,
						<&aggre2_noc MASTER_QUP_1 QCOM_ICC_TAG_ALWAYS
						 &mc_virt SLAVE_EBI1 QCOM_ICC_TAG_ALWAYS>;
				interconnect-names = "qup-core",
						     "qup-config",
						     "qup-memory";
				power-domains = <&rpmhpd SA7255P_CX>;
				status = "disabled";
			};

			spi12: spi@a90000 {
				compatible = "qcom,geni-spi";
				reg = <0x0 0xa90000 0x0 0x4000>;
				#address-cells = <1>;
				#size-cells = <0>;
				interrupts = <GIC_SPI 357 IRQ_TYPE_LEVEL_HIGH>;
				clocks = <&gcc GCC_QUPV3_WRAP1_S4_CLK>;
				clock-names = "se";
				interconnects = <&clk_virt MASTER_QUP_CORE_1 QCOM_ICC_TAG_ALWAYS
						 &clk_virt SLAVE_QUP_CORE_1 QCOM_ICC_TAG_ALWAYS>,
						<&gem_noc MASTER_APPSS_PROC QCOM_ICC_TAG_ALWAYS
						 &config_noc SLAVE_QUP_1 QCOM_ICC_TAG_ALWAYS>,
						<&aggre2_noc MASTER_QUP_1 QCOM_ICC_TAG_ALWAYS
						 &mc_virt SLAVE_EBI1 QCOM_ICC_TAG_ALWAYS>;
				interconnect-names = "qup-core",
						     "qup-config",
						     "qup-memory";
				power-domains = <&rpmhpd SA7255P_CX>;
				status = "disabled";
			};

			uart12: serial@a90000 {
				compatible = "qcom,geni-uart";
				reg = <0x0 0xa90000 0x0 0x4000>;
				interrupts = <GIC_SPI 356 IRQ_TYPE_LEVEL_HIGH>;
				clocks = <&gcc GCC_QUPV3_WRAP1_S4_CLK>;
				clock-names = "se";
				interconnects = <&clk_virt MASTER_QUP_CORE_1 QCOM_ICC_TAG_ALWAYS
						 &clk_virt SLAVE_QUP_CORE_1 QCOM_ICC_TAG_ALWAYS>,
						<&gem_noc MASTER_APPSS_PROC QCOM_ICC_TAG_ALWAYS
						 &config_noc SLAVE_QUP_1 QCOM_ICC_TAG_ALWAYS>;
				interconnect-names = "qup-core", "qup-config";
				power-domains = <&rpmhpd SA7255P_CX>;
				status = "disabled";
			};

			i2c13: i2c@a94000 {
				compatible = "qcom,geni-i2c";
				reg = <0x0 0xa94000 0x0 0x4000>;
				#address-cells = <1>;
				#size-cells = <0>;
				interrupts = <GIC_SPI 358 IRQ_TYPE_LEVEL_HIGH>;
				clocks = <&gcc GCC_QUPV3_WRAP1_S5_CLK>;
				clock-names = "se";
				interconnects = <&clk_virt MASTER_QUP_CORE_1 QCOM_ICC_TAG_ALWAYS
						 &clk_virt SLAVE_QUP_CORE_1 QCOM_ICC_TAG_ALWAYS>,
						<&gem_noc MASTER_APPSS_PROC QCOM_ICC_TAG_ALWAYS
						 &config_noc SLAVE_QUP_1 QCOM_ICC_TAG_ALWAYS>,
						<&aggre2_noc MASTER_QUP_1 QCOM_ICC_TAG_ALWAYS
						 &mc_virt SLAVE_EBI1 QCOM_ICC_TAG_ALWAYS>;
				interconnect-names = "qup-core",
						     "qup-config",
						     "qup-memory";
				power-domains = <&rpmhpd SA7255P_CX>;
				status = "disabled";
			};

			spi13: spi@a94000 {
				compatible = "qcom,geni-spi";
				reg = <0x0 0xa94000 0x0 0x4000>;
				#address-cells = <1>;
				#size-cells = <0>;
				interrupts = <GIC_SPI 358 IRQ_TYPE_LEVEL_HIGH>;
				clocks = <&gcc GCC_QUPV3_WRAP1_S5_CLK>;
				clock-names = "se";
				interconnects = <&clk_virt MASTER_QUP_CORE_1 QCOM_ICC_TAG_ALWAYS
						 &clk_virt SLAVE_QUP_CORE_1 QCOM_ICC_TAG_ALWAYS>,
						<&gem_noc MASTER_APPSS_PROC QCOM_ICC_TAG_ALWAYS
						 &config_noc SLAVE_QUP_1 QCOM_ICC_TAG_ALWAYS>,
						<&aggre2_noc MASTER_QUP_1 QCOM_ICC_TAG_ALWAYS
						 &mc_virt SLAVE_EBI1 QCOM_ICC_TAG_ALWAYS>;
				interconnect-names = "qup-core",
						     "qup-config",
						     "qup-memory";
				power-domains = <&rpmhpd SA7255P_CX>;
				status = "disabled";
			};

			i2c14: i2c@a98000 {
				compatible = "qcom,geni-i2c";
				reg = <0x0 0xa98000 0x0 0x4000>;
				#address-cells = <1>;
				#size-cells = <0>;
				interrupts = <GIC_SPI 835 IRQ_TYPE_LEVEL_HIGH>;
				clocks = <&gcc GCC_QUPV3_WRAP1_S6_CLK>;
				clock-names = "se";
				interconnects = <&clk_virt MASTER_QUP_CORE_1 QCOM_ICC_TAG_ALWAYS
						 &clk_virt SLAVE_QUP_CORE_1 QCOM_ICC_TAG_ALWAYS>,
						<&gem_noc MASTER_APPSS_PROC QCOM_ICC_TAG_ALWAYS
						 &config_noc SLAVE_QUP_1 QCOM_ICC_TAG_ALWAYS>,
						<&aggre2_noc MASTER_QUP_1 QCOM_ICC_TAG_ALWAYS
						 &mc_virt SLAVE_EBI1 QCOM_ICC_TAG_ALWAYS>;
				interconnect-names = "qup-core",
						     "qup-config",
						     "qup-memory";
				power-domains = <&rpmhpd SA7255P_CX>;
				status = "disabled";
			};

			i2c15: i2c@a9c000 {
				compatible = "qcom,geni-i2c";
				reg = <0x0 0xa9c000 0x0 0x4000>;
				#address-cells = <1>;
				#size-cells = <0>;
				interrupts = <GIC_SPI 125 IRQ_TYPE_LEVEL_HIGH>;
				clocks = <&gcc GCC_QUPV3_WRAP1_S7_CLK>;
				clock-names = "se";
				interconnects = <&clk_virt MASTER_QUP_CORE_1 QCOM_ICC_TAG_ALWAYS
						 &clk_virt SLAVE_QUP_CORE_1 QCOM_ICC_TAG_ALWAYS>,
						<&gem_noc MASTER_APPSS_PROC QCOM_ICC_TAG_ALWAYS
						 &config_noc SLAVE_QUP_1 QCOM_ICC_TAG_ALWAYS>,
						<&aggre2_noc MASTER_QUP_1 QCOM_ICC_TAG_ALWAYS
						 &mc_virt SLAVE_EBI1 QCOM_ICC_TAG_ALWAYS>;
				interconnect-names = "qup-core",
						     "qup-config",
						     "qup-memory";
				power-domains = <&rpmhpd SA7255P_CX>;
				status = "disabled";
			};
		};

		qupv3_id_3: geniqup@bc0000 {
			compatible = "qcom,geni-se-qup";
			reg = <0x0 0xbc0000 0x0 0x2000>;
			#address-cells = <2>;
			#size-cells = <2>;
			ranges;
			clock-names = "m-ahb", "s-ahb";
			clocks = <&gcc GCC_QUPV3_WRAP_3_M_AHB_CLK>,
				<&gcc GCC_QUPV3_WRAP_3_S_AHB_CLK>;
			iommus = <&apps_smmu 0x43 0x0>;
			status = "disabled";

			i2c16: i2c@b80000 {
				compatible = "qcom,geni-i2c";
				reg = <0x0 0xb80000 0x0 0x4000>;
				#address-cells = <1>;
				#size-cells = <0>;
				interrupts = <GIC_SPI 830 IRQ_TYPE_LEVEL_HIGH>;
				clocks = <&gcc GCC_QUPV3_WRAP3_S0_CLK>;
				clock-names = "se";
				interconnects = <&clk_virt MASTER_QUP_CORE_3 QCOM_ICC_TAG_ALWAYS
						&clk_virt SLAVE_QUP_CORE_3 QCOM_ICC_TAG_ALWAYS>,
					   <&gem_noc MASTER_APPSS_PROC QCOM_ICC_TAG_ALWAYS
						&config_noc SLAVE_QUP_3 QCOM_ICC_TAG_ALWAYS>,
					   <&aggre1_noc MASTER_QUP_3 QCOM_ICC_TAG_ALWAYS
						&mc_virt SLAVE_EBI1 QCOM_ICC_TAG_ALWAYS>;
				interconnect-names = "qup-core",
							 "qup-config",
							 "qup-memory";
				power-domains = <&rpmhpd SA7255P_CX>;
				status = "disabled";
			};

			spi16: spi@b80000 {
				compatible = "qcom,geni-spi";
				reg = <0x0 0xb80000 0x0 0x4000>;
				#address-cells = <1>;
				#size-cells = <0>;
				interrupts = <GIC_SPI 830 IRQ_TYPE_LEVEL_HIGH>;
				clocks = <&gcc GCC_QUPV3_WRAP3_S0_CLK>;
				clock-names = "se";
				interconnects = <&clk_virt MASTER_QUP_CORE_3 QCOM_ICC_TAG_ALWAYS
						&clk_virt SLAVE_QUP_CORE_3 QCOM_ICC_TAG_ALWAYS>,
					   <&gem_noc MASTER_APPSS_PROC QCOM_ICC_TAG_ALWAYS
						&config_noc SLAVE_QUP_3 QCOM_ICC_TAG_ALWAYS>,
					   <&aggre1_noc MASTER_QUP_3 QCOM_ICC_TAG_ALWAYS
						&mc_virt SLAVE_EBI1 QCOM_ICC_TAG_ALWAYS>;
				interconnect-names = "qup-core",
							 "qup-config",
							 "qup-memory";
				power-domains = <&rpmhpd SA7255P_CX>;
				status = "disabled";
			};
		};

		ufs_mem_hc: ufs@1d84000 {
			compatible = "qcom,sa7255p-ufshc", "qcom,ufshc", "jedec,ufs-2.0";
			reg = <0x0 0x01d84000 0x0 0x3000>;
			interrupts = <GIC_SPI 265 IRQ_TYPE_LEVEL_HIGH>;
			phys = <&ufs_mem_phy>;
			phy-names = "ufsphy";
			lanes-per-direction = <2>;
			#reset-cells = <1>;
			resets = <&gcc GCC_UFS_PHY_BCR>;
			reset-names = "rst";
			power-domains = <&gcc UFS_PHY_GDSC>;
			required-opps = <&rpmhpd_opp_nom>;
			iommus = <&apps_smmu 0x100 0x0>;
			dma-coherent;
			clocks = <&gcc GCC_UFS_PHY_AXI_CLK>,
				 <&gcc GCC_AGGRE_UFS_PHY_AXI_CLK>,
				 <&gcc GCC_UFS_PHY_AHB_CLK>,
				 <&gcc GCC_UFS_PHY_UNIPRO_CORE_CLK>,
				 <&rpmhcc RPMH_CXO_CLK>,
				 <&gcc GCC_UFS_PHY_TX_SYMBOL_0_CLK>,
				 <&gcc GCC_UFS_PHY_RX_SYMBOL_0_CLK>,
				 <&gcc GCC_UFS_PHY_RX_SYMBOL_1_CLK>;
			clock-names = "core_clk",
				      "bus_aggr_clk",
				      "iface_clk",
				      "core_clk_unipro",
				      "ref_clk",
				      "tx_lane0_sync_clk",
				      "rx_lane0_sync_clk",
				      "rx_lane1_sync_clk";
			freq-table-hz = <75000000 300000000>,
					<0 0>,
					<0 0>,
					<75000000 300000000>,
					<0 0>,
					<0 0>,
					<0 0>,
					<0 0>;

			status = "disabled";
		};

		ufs_mem_phy: phy@1d87000 {
			compatible = "qcom,sa7255p-qmp-ufs-phy";
			reg = <0x0 0x01d87000 0x0 0xe10>;
			clocks = <&rpmhcc RPMH_CXO_CLK>,
				 <&gcc GCC_UFS_PHY_PHY_AUX_CLK>;
			clock-names = "ref", "ref_aux";
			power-domains = <&gcc UFS_PHY_GDSC>;
			resets = <&ufs_mem_hc 0>;
			reset-names = "ufsphy";
			#phy-cells = <0>;
			status = "disabled";
		};

		tcsr_mutex: hwlock@1f40000 {
			compatible = "qcom,tcsr-mutex";
			reg = <0x0 0x01f40000 0x0 0x20000>;
			#hwlock-cells = <1>;
		};

		usb_0_hsphy: phy@8904000 {
			compatible = "qcom,sa7255p-usb-hs-phy",
				     "qcom,usb-snps-hs-5nm-phy";
			reg = <0x0 0x08904000 0x0 0x120>;
			clocks = <&rpmhcc RPMH_CXO_CLK>;
			clock-names = "ref";
			resets = <&gcc GCC_USB2_PHY_PRIM_BCR>;

			#phy-cells = <0>;

			status = "disabled";
		};

		usb_0_qmpphy: phy@8907000 {
			compatible = "qcom,sa7255p-qmp-usb3-uni-phy";
			reg = <0x0 0x08907000 0x0 0x2000>;

			clocks = <&gcc GCC_USB3_PRIM_PHY_AUX_CLK>,
				 <&gcc GCC_USB_CLKREF_EN>,
				 <&gcc GCC_USB3_PRIM_PHY_COM_AUX_CLK>,
				 <&gcc GCC_USB3_PRIM_PHY_PIPE_CLK>;
			clock-names = "aux", "ref", "com_aux", "pipe";

			resets = <&gcc GCC_USB3_PHY_PRIM_BCR>,
				 <&gcc GCC_USB3PHY_PHY_PRIM_BCR>;
			reset-names = "phy", "phy_phy";

			power-domains = <&gcc USB30_PRIM_GDSC>;

			#clock-cells = <0>;
			clock-output-names = "usb3_prim_phy_pipe_clk_src";

			#phy-cells = <0>;

			status = "disabled";
		};

		usb_0: usb@a6f8800 {
			compatible = "qcom,sa7255p-dwc3", "qcom,dwc3";
			reg = <0x0 0x0a6f8800 0x0 0x400>;
			#address-cells = <2>;
			#size-cells = <2>;
			ranges;

			clocks = <&gcc GCC_CFG_NOC_USB3_PRIM_AXI_CLK>,
				 <&gcc GCC_USB30_PRIM_MASTER_CLK>,
				 <&gcc GCC_AGGRE_USB3_PRIM_AXI_CLK>,
				 <&gcc GCC_USB30_PRIM_SLEEP_CLK>,
				 <&gcc GCC_USB30_PRIM_MOCK_UTMI_CLK>;
			clock-names = "cfg_noc", "core", "iface", "sleep", "mock_utmi";

			assigned-clocks = <&gcc GCC_USB30_PRIM_MOCK_UTMI_CLK>,
					  <&gcc GCC_USB30_PRIM_MASTER_CLK>;
			assigned-clock-rates = <19200000>, <200000000>;

			interrupts-extended = <&intc GIC_SPI 287 IRQ_TYPE_LEVEL_HIGH>,
					      <&pdc 14 IRQ_TYPE_EDGE_BOTH>,
					      <&pdc 15 IRQ_TYPE_EDGE_BOTH>,
					      <&pdc 12 IRQ_TYPE_LEVEL_HIGH>;
			interrupt-names = "pwr_event",
					  "dp_hs_phy_irq",
					  "dm_hs_phy_irq",
					  "ss_phy_irq";

			power-domains = <&gcc USB30_PRIM_GDSC>;
			required-opps = <&rpmhpd_opp_nom>;

			resets = <&gcc GCC_USB30_PRIM_BCR>;

			interconnects = <&aggre1_noc MASTER_USB3_0 0 &mc_virt SLAVE_EBI1 0>,
					<&gem_noc MASTER_APPSS_PROC 0 &config_noc SLAVE_USB3_0 0>;
			interconnect-names = "usb-ddr", "apps-usb";

			wakeup-source;

			status = "disabled";

			usb_0_dwc3: usb@a600000 {
				compatible = "snps,dwc3";
				reg = <0x0 0x0a600000 0x0 0xe000>;
				interrupts = <GIC_SPI 292 IRQ_TYPE_LEVEL_HIGH>;
				iommus = <&apps_smmu 0x080 0x0>;
				phys = <&usb_0_hsphy>, <&usb_0_qmpphy>;
				phy-names = "usb2-phy", "usb3-phy";
				snps,dis-u1-entry-quirk;
				snps,dis-u2-entry-quirk;
			};
		};

		usb_1_hsphy: phy@8906000 {
			compatible = "qcom,sa7255p-usb-hs-phy",
				     "qcom,usb-snps-hs-5nm-phy";
			reg = <0x0 0x08906000 0x0 0x120>;
			clocks = <&gcc GCC_USB_CLKREF_EN>;
			clock-names = "ref";
			resets = <&gcc GCC_USB3_PHY_TERT_BCR>;

			#phy-cells = <0>;

			status = "disabled";
		};

		usb_1: usb@a4f8800 {
			compatible = "qcom,sa7255p-dwc3", "qcom,dwc3";
			reg = <0x0 0x0a4f8800 0x0 0x400>;
			#address-cells = <2>;
			#size-cells = <2>;
			ranges;

			clocks = <&gcc GCC_CFG_NOC_USB2_PRIM_AXI_CLK>,
				 <&gcc GCC_USB20_MASTER_CLK>,
				 <&gcc GCC_AGGRE_USB2_PRIM_AXI_CLK>,
				 <&gcc GCC_USB20_SLEEP_CLK>,
				 <&gcc GCC_USB20_MOCK_UTMI_CLK>;
			clock-names = "cfg_noc", "core", "iface", "sleep", "mock_utmi";

			assigned-clocks = <&gcc GCC_USB20_MOCK_UTMI_CLK>,
					  <&gcc GCC_USB20_MASTER_CLK>;
			assigned-clock-rates = <19200000>, <200000000>;

			interrupts-extended = <&intc GIC_SPI 444 IRQ_TYPE_LEVEL_HIGH>,
					      <&pdc 10 IRQ_TYPE_EDGE_BOTH>,
					      <&pdc 9 IRQ_TYPE_EDGE_BOTH>;
			interrupt-names = "pwr_event",
					  "dp_hs_phy_irq",
					  "dm_hs_phy_irq";

			power-domains = <&gcc USB20_PRIM_GDSC>;
			required-opps = <&rpmhpd_opp_nom>;

			resets = <&gcc GCC_USB20_PRIM_BCR>;

			interconnects = <&aggre1_noc MASTER_USB2 0 &mc_virt SLAVE_EBI1 0>,
					<&gem_noc MASTER_APPSS_PROC 0 &config_noc SLAVE_USB2 0>;
			interconnect-names = "usb-ddr", "apps-usb";

			wakeup-source;

			status = "disabled";

			usb_1_dwc3: usb@a400000 {
				compatible = "snps,dwc3";
				reg = <0x0 0x0a400000 0x0 0xe000>;
				interrupts = <GIC_SPI 442 IRQ_TYPE_LEVEL_HIGH>;
				iommus = <&apps_smmu 0x020 0x0>;
				phys = <&usb_1_hsphy>;
				phy-names = "usb2-phy";
			};
		};

		psci {
			compatible = "arm,psci-1.0";
			method = "smc";
		};

		serdes0: phy@8909000 {
			compatible = "qcom,sa7255p-dwmac-sgmii-phy";
			reg = <0x0 0x08909000 0x0 0xe10>;
			clocks = <&gcc GCC_SGMI_CLKREF_EN>;
			clock-names = "sgmi_ref";
			#phy-cells = <0>;
			status = "disabled";
		};

		pdc: interrupt-controller@b220000 {
			compatible = "qcom,sa7255p-pdc", "qcom,pdc";
			reg = <0x0 0xb220000 0x0 0x10000>,
			      <0x0 0x17c000f0 0x0 0x64>;
			qcom,pdc-ranges = <0 480 40>,
					  <40 140 14>,
					  <54 263 1>,
					  <55 306 4>,
					  <59 312 3>,
					  <62 374 2>,
					  <64 434 2>,
					  <66 438 2>,
					  <70 520 1>,
					  <73 523 1>,
					  <118 568 6>,
					  <124 609 3>,
					  <159 638 1>,
					  <160 720 3>,
					  <169 728 30>,
					  <199 416 2>,
					  <201 449 1>,
					  <202 89 1>,
					  <203 451 1>,
					  <204 462 1>,
					  <205 264 1>,
					  <206 579 1>,
					  <207 653 1>,
					  <208 656 1>,
					  <209 659 1>,
					  <210 122 1>,
					  <211 699 1>,
					  <212 705 1>,
					  <213 450 1>,
					  <214 643 2>,
					  <216 646 5>,
					  <221 390 5>,
					  <226 700 2>,
					  <228 440 1>,
					  <229 663 1>,
					  <230 524 2>,
					  <232 612 3>,
					  <235 723 5>;
			#interrupt-cells = <2>;
			interrupt-parent = <&intc>;
			interrupt-controller;
		};

		spmi_bus: spmi@c440000 {
			compatible = "qcom,spmi-pmic-arb";
			reg = <0x0 0x0c440000 0x0 0x1100>,
			      <0x0 0x0c600000 0x0 0x2000000>,
			      <0x0 0x0e600000 0x0 0x100000>,
			      <0x0 0x0e700000 0x0 0xa0000>,
			      <0x0 0x0c40a000 0x0 0x26000>;
			reg-names = "core",
				    "chnls",
				    "obsrvr",
				    "intr",
				    "cnfg";
			qcom,channel = <0>;
			qcom,ee = <0>;
			interrupts-extended = <&pdc 1 IRQ_TYPE_LEVEL_HIGH>;
			interrupt-names = "periph_irq";
			interrupt-controller;
			#interrupt-cells = <4>;
			#address-cells = <2>;
			#size-cells = <0>;
		};

		intc: interrupt-controller@17a00000 {
			compatible = "arm,gic-v3";
			#interrupt-cells = <3>;
			interrupt-controller;
			#redistributor-regions = <1>;
			redistributor-stride = <0x0 0x20000>;
			reg = <0x0 0x17a00000 0x0 0x10000>,     /* GICD */
			      <0x0 0x17a60000 0x0 0x100000>;    /* GICR * 8 */
			interrupts = <GIC_PPI 9 IRQ_TYPE_LEVEL_HIGH>;
		};

		arch_timer: timer {
			compatible = "arm,armv8-timer";
			interrupts = <GIC_PPI 13 (GIC_CPU_MASK_SIMPLE(8) | IRQ_TYPE_LEVEL_LOW)>,
				     <GIC_PPI 14 (GIC_CPU_MASK_SIMPLE(8) | IRQ_TYPE_LEVEL_LOW)>,
				     <GIC_PPI 11 (GIC_CPU_MASK_SIMPLE(8) | IRQ_TYPE_LEVEL_LOW)>,
				     <GIC_PPI 12 (GIC_CPU_MASK_SIMPLE(8) | IRQ_TYPE_LEVEL_LOW)>;
			clock-frequency = <19200000>;
		};

		memtimer: timer@17c20000 {
			#address-cells = <1>;
			#size-cells = <1>;
			ranges = <0x0 0x0 0x0 0x20000000>;
			compatible = "arm,armv7-timer-mem";
			reg = <0x0 0x17c20000 0x0 0x1000>;
			clock-frequency = <19200000>;

			frame@17c21000 {
				frame-number = <0>;
				interrupts = <GIC_SPI 8 IRQ_TYPE_LEVEL_HIGH>,
					     <GIC_SPI 6 IRQ_TYPE_LEVEL_HIGH>;
				reg = <0x17c21000 0x1000>,
				      <0x17c22000 0x1000>;
			};

			frame@17c23000 {
				frame-number = <1>;
				interrupts = <GIC_SPI 9 IRQ_TYPE_LEVEL_HIGH>;
				reg = <0x17c23000 0x1000>;
				status = "disabled";
			};

			frame@17c25000 {
				frame-number = <2>;
				interrupts = <GIC_SPI 10 IRQ_TYPE_LEVEL_HIGH>;
				reg = <0x17c25000 0x1000>;
				status = "disabled";
			};

			frame@17c27000 {
				frame-number = <3>;
				interrupts = <GIC_SPI 11 IRQ_TYPE_LEVEL_HIGH>;
				reg = <0x17c27000 0x1000>;
				status = "disabled";
			};

			frame@17c29000 {
				frame-number = <4>;
				interrupts = <GIC_SPI 12 IRQ_TYPE_LEVEL_HIGH>;
				reg = <0x17c29000 0x1000>;
				status = "disabled";
			};

			frame@17c2b000 {
				frame-number = <5>;
				interrupts = <GIC_SPI 13 IRQ_TYPE_LEVEL_HIGH>;
				reg = <0x17c2b000 0x1000>;
				status = "disabled";
			};

			frame@17c2d000 {
				frame-number = <6>;
				interrupts = <GIC_SPI 14 IRQ_TYPE_LEVEL_HIGH>;
				reg = <0x17c2d000 0x1000>;
				status = "disabled";
			};
		};

		apps_rsc: rsc@18200000 {
			compatible = "qcom,rpmh-rsc";
			reg = <0x0 0x18200000 0x0 0x10000>,
			      <0x0 0x18210000 0x0 0x10000>,
			      <0x0 0x18220000 0x0 0x10000>;
			reg-names = "drv-0", "drv-1", "drv-2";
			interrupts = <GIC_SPI 3 IRQ_TYPE_LEVEL_HIGH>,
				     <GIC_SPI 4 IRQ_TYPE_LEVEL_HIGH>,
				     <GIC_SPI 5 IRQ_TYPE_LEVEL_HIGH>;
			qcom,tcs-offset = <0xd00>;
			qcom,drv-id = <2>;
			qcom,tcs-config = <ACTIVE_TCS 2>,
					  <SLEEP_TCS 3>,
					  <WAKE_TCS 3>,
					  <CONTROL_TCS 0>;
			label = "apps_rsc";

			apps_bcm_voter: bcm-voter {
				compatible = "qcom,bcm-voter";
			};

			rpmhcc: clock-controller {
				compatible = "qcom,sa8775p-rpmh-clk";
				#clock-cells = <1>;
				clock-names = "xo";
				clocks = <&xo_board_clk>;
			};

			rpmhpd: power-controller {
				compatible = "qcom,sa7255p-rpmhpd";
				#power-domain-cells = <1>;
				operating-points-v2 = <&rpmhpd_opp_table>;

				rpmhpd_opp_table: opp-table {
					compatible = "operating-points-v2";

					rpmhpd_opp_ret: opp-0 {
						opp-level = <RPMH_REGULATOR_LEVEL_RETENTION>;
					};

					rpmhpd_opp_min_svs: opp-1 {
						opp-level = <RPMH_REGULATOR_LEVEL_MIN_SVS>;
					};

					rpmhpd_opp_low_svs: opp2 {
						opp-level = <RPMH_REGULATOR_LEVEL_LOW_SVS>;
					};

					rpmhpd_opp_svs: opp3 {
						opp-level = <RPMH_REGULATOR_LEVEL_SVS>;
					};

					rpmhpd_opp_svs_l1: opp-4 {
						opp-level = <RPMH_REGULATOR_LEVEL_SVS_L1>;
					};

					rpmhpd_opp_nom: opp-5 {
						opp-level = <RPMH_REGULATOR_LEVEL_NOM>;
					};

					rpmhpd_opp_nom_l1: opp-6 {
						opp-level = <RPMH_REGULATOR_LEVEL_NOM_L1>;
					};

					rpmhpd_opp_nom_l2: opp-7 {
						opp-level = <RPMH_REGULATOR_LEVEL_NOM_L2>;
					};

					rpmhpd_opp_turbo: opp-8 {
						opp-level = <RPMH_REGULATOR_LEVEL_TURBO>;
					};

					rpmhpd_opp_turbo_l1: opp-9 {
						opp-level = <RPMH_REGULATOR_LEVEL_TURBO_L1>;
					};
				};
			};
		};

		tlmm: pinctrl@f000000 {
			compatible = "qcom,sa7255p-tlmm";
			reg = <0x0 0x0f000000 0x0 0x1000000>;
			interrupts = <GIC_SPI 208 IRQ_TYPE_LEVEL_HIGH>;
			gpio-controller;
			#gpio-cells = <2>;
			interrupt-controller;
			#interrupt-cells = <2>;
			gpio-ranges = <&tlmm 0 0 133>;
			wakeup-parent = <&pdc>;

			sec_tdm_sck {
				sec_tdm_sck_sleep: sec_tdm_sck_sleep {
					mux {
						pins = "gpio98";
						function = "gpio";
					};

					config {
						pins = "gpio98";
						drive-strength = <2>;   /* 2 mA */
						bias-pull-down;         /* PULL DOWN */
						input-enable;
					};
				};

				sec_tdm_sck_active: sec_tdm_sck_active {
					mux {
						pins = "gpio98";
						function = "mi2s1_sck";
					};

					config {
						pins = "gpio98";
						drive-strength = <8>;   /* 8 mA */
						bias-disable;           /* NO PULL */
						input-enable;
					};
				};
			};

			sec_tdm_ws {
				sec_tdm_ws_sleep: sec_tdm_ws_sleep {
					mux {
						pins = "gpio99";
						function = "gpio";
					};

					config {
						pins = "gpio99";
						drive-strength = <2>;   /* 2 mA */
						bias-pull-down;         /* PULL DOWN */
						input-enable;
					};
				};

				sec_tdm_ws_active: sec_tdm_ws_active {
					mux {
						pins = "gpio99";
						function = "mi2s1_ws";
					};

					config {
						pins = "gpio99";
						drive-strength = <8>;   /* 8 mA */
						bias-disable;           /* NO PULL */
						output-high;
					};
				};
			};

			sec_tdm_din {
				sec_tdm_din_sleep: sec_tdm_din_sleep {
					mux {
						pins = "gpio100";
						function = "gpio";
					};

					config {
						pins = "gpio100";
						drive-strength = <2>;   /* 2 mA */
						bias-pull-down;         /* PULL DOWN */
						input-enable;
					};
				};

				sec_tdm_din_active: sec_tdm_din_active {
					mux {
						pins = "gpio100";
						function = "mi2s1_data0";
					};

					config {
						pins = "gpio100";
						drive-strength = <8>;   /* 8 mA */
						bias-disable;           /* NO PULL */
					};
				};
			};

			sec_tdm_dout {
				sec_tdm_dout_sleep: sec_tdm_dout_sleep {
					mux {
						pins = "gpio101";
						function = "gpio";
					};

					config {
						pins = "gpio101";
						drive-strength = <2>;   /* 2 mA */
						bias-pull-down;         /* PULL DOWN */
						input-enable;
					};
				};

				sec_tdm_dout_active: sec_tdm_dout_active {
					mux {
						pins = "gpio101";
						function = "mi2s1_data1";
					};

					config {
						pins = "gpio101";
						drive-strength = <8>;   /* 8 mA */
						bias-disable;           /* NO PULL */
						output-high;
					};
				};
			};

			tert_tdm_sck {
				tert_tdm_sck_sleep: tert_tdm_sck_sleep {
					mux {
						pins = "gpio102";
						function = "gpio";
					};

					config {
						pins = "gpio102";
						drive-strength = <2>;   /* 2 mA */
						bias-pull-down;         /* PULL DOWN */
						input-enable;
					};
				};

				tert_tdm_sck_active: tert_tdm_sck_active {
					mux {
						pins = "gpio102";
						function = "mi2s2_sck";
					};

					config {
						pins = "gpio102";
						drive-strength = <8>;   /* 8 mA */
						bias-disable;           /* NO PULL */
						output-high;
					};
				};
			};

			tert_tdm_ws {
				tert_tdm_ws_sleep: tert_tdm_ws_sleep {
					mux {
						pins = "gpio103";
						function = "gpio";
					};

					config {
						pins = "gpio103";
						drive-strength = <2>;   /* 2 mA */
						bias-pull-down;         /* PULL DOWN */
						input-enable;
					};
				};

				tert_tdm_ws_active: tert_tdm_ws_active {
					mux {
						pins = "gpio103";
						function = "mi2s2_ws";
					};

					config {
						pins = "gpio103";
						drive-strength = <8>;   /* 8 mA */
						bias-disable;           /* NO PULL */
						output-high;
					};
				};
			};

			tert_tdm_din {
				tert_tdm_din_sleep: tert_tdm_din_sleep {
					mux {
						pins = "gpio104";
						function = "gpio";
					};

					config {
						pins = "gpio104";
						drive-strength = <2>;   /* 2 mA */
						bias-pull-down;         /* PULL DOWN */
						input-enable;
					};
				};

				tert_tdm_din_active: tert_tdm_din_active {
					mux {
						pins = "gpio104";
						function = "mi2s2_data0";
					};

					config {
						pins = "gpio104";
						drive-strength = <8>;   /* 8 mA */
						bias-disable;           /* NO PULL */
					};
				};
			};

			tert_tdm_dout {
				tert_tdm_dout_sleep: tert_tdm_dout_sleep {
					mux {
						pins = "gpio105";
						function = "gpio";
					};

					config {
						pins = "gpio105";
						drive-strength = <2>;   /* 2 mA */
						bias-pull-down;         /* PULL DOWN */
						input-enable;
					};
				};

				tert_tdm_dout_active: tert_tdm_dout_active {
					mux {
						pins = "gpio105";
						function = "mi2s2_data1";
					};

					config {
						pins = "gpio105";
						drive-strength = <8>;   /* 8 mA */
						bias-disable;           /* NO PULL */
						output-high;
					};
				};
			};

			hs0_i2s_sck {
				hs0_i2s_sck_sleep: hs0_i2s_sck_sleep {
					mux {
						pins = "gpio106";
						function = "gpio";
					};

					config {
						pins = "gpio106";
						drive-strength = <2>;   /* 2 mA */
						bias-pull-down;         /* PULL DOWN */
						input-enable;
					};
				};

				hs0_i2s_sck_active: hs0_i2s_sck_active {
					mux {
						pins = "gpio106";
						function = "hs0_mi2s";
					};

					config {
						pins = "gpio106";
						drive-strength = <8>;   /* 8 mA */
						bias-disable;           /* NO PULL */
						output-high;
					};
				};
			};

			hs0_i2s_ws {
				hs0_i2s_ws_sleep: hs0_i2s_ws_sleep {
					mux {
						pins = "gpio107";
						function = "gpio";
					};

					config {
						pins = "gpio107";
						drive-strength = <2>;   /* 2 mA */
						bias-pull-down;         /* PULL DOWN */
						input-enable;
					};
				};

				hs0_i2s_ws_active: hs0_i2s_ws_active {
					mux {
						pins = "gpio107";
						function = "hs0_mi2s";
					};

					config {
						pins = "gpio107";
						drive-strength = <8>;   /* 8 mA */
						bias-disable;           /* NO PULL */
						output-high;
					};
				};
			};

			hs0_i2s_data0 {
				hs0_i2s_data0_sleep: hs0_i2s_data0_sleep {
					mux {
						pins = "gpio108";
						function = "gpio";
					};

					config {
						pins = "gpio108";
						drive-strength = <2>;   /* 2 mA */
						bias-pull-down;         /* PULL DOWN */
						input-enable;
					};
				};

				hs0_i2s_data0_active: hs0_i2s_data0_active {
					mux {
						pins = "gpio108";
						function = "hs0_mi2s";
					};

					config {
						pins = "gpio108";
						drive-strength = <8>;   /* 8 mA */
						bias-disable;           /* NO PULL */
					};
				};
			};

			hs0_i2s_data1 {
				hs0_i2s_data1_sleep: hs0_i2s_data1_sleep {
					mux {
						pins = "gpio109";
						function = "gpio";
					};

					config {
						pins = "gpio109";
						drive-strength = <2>;   /* 2 mA */
						bias-pull-down;         /* PULL DOWN */
						input-enable;
					};
				};

				hs0_i2s_data1_active: hs0_i2s_data1_active {
					mux {
						pins = "gpio109";
						function = "hs0_mi2s";
					};

					config {
						pins = "gpio109";
						drive-strength = <8>;   /* 8 mA */
						bias-disable;           /* NO PULL */
						output-high;
					};
				};
			};

			audio_internal_mclk1 {
				audio_internal_mclk1_sleep: audio_internal_mclk1_sleep {
					mux {
						pins = "gpio97";
						function = "gpio";
					};

					config {
						pins = "gpio97";
						drive-strength = <2>;   /* 2 mA */
						bias-pull-down;         /* PULL DOWN */
					};
				};

				audio_internal_mclk1_active: audio_internal_mclk1_active {
					mux {
						pins = "gpio97";
						function = "mi2s_mclk0";
					};

					config {
						pins = "gpio97";
						drive-strength = <8>;   /* 8 mA */
						bias-disable;           /* NO PULL */
						output-high;
					};
				};
			};

			cci0_sda_default: cci0_sda_default {
				mux {
					/* CLK, DATA */
					pins = "gpio57";
					function = "cci_i2c_sda";
				};
				config {
					pins = "gpio57";
					bias-pull-up; /* PULL UP*/
					drive-strength = <2>; /* 2 MA */
				};
			};

			cci0_scl_default: cci0_scl_default {
				mux {
					/* CLK, DATA */
					pins = "gpio58";
					function = "cci_i2c_scl";
				};
				config {
					pins = "gpio58";
					bias-pull-up; /* PULL UP*/
					drive-strength = <2>; /* 2 MA */
				};
			};

			cci2_sda_default: cci2_sda_default {
				mux {
					/* CLK, DATA */
					pins = "gpio59";
					function = "cci_i2c_sda";
				};
				config {
					pins = "gpio59";
					bias-pull-up; /* PULL UP*/
					drive-strength = <2>; /* 2 MA */
				};
			};

			cci2_scl_default: cci2_scl_default {
				mux {
					/* CLK, DATA */
					pins = "gpio60";
					function = "cci_i2c_scl";
				};
				config {
					pins = "gpio60";
					bias-pull-up; /* PULL UP*/
					drive-strength = <2>; /* 2 MA */
				};
			};

			cci4_sda_default: cci4_sda_default {
				mux {
					/* CLK, DATA */
					pins = "gpio61";
					function = "cci_i2c_sda";
				};
				config {
					pins = "gpio61";
					bias-pull-up; /* PULL UP*/
					drive-strength = <2>; /* 2 MA */
				};
			};

			cci4_scl_default: cci4_scl_default {
				mux {
					/* CLK, DATA */
					pins = "gpio62";
					function = "cci_i2c_scl";
				};
				config {
					pins = "gpio62";
					bias-pull-up; /* PULL UP*/
					drive-strength = <2>; /* 2 MA */
				};
			};

			fsync0_default: fsync0_default {
				mux {
					/* CLK, DATA */
					pins = "gpio63";
					function = "cci_timer0";
				};

				config {
					pins = "gpio63";
					bias-pull-up; /* PULL UP*/
					drive-strength = <2>; /* 2 MA */
				};
			};

			fsync1_default: fsync1_default {
				mux {
					/* CLK, DATA */
					pins = "gpio64";
					function = "cci_timer1";
				};

				config {
					pins = "gpio64";
					bias-pull-up; /* PULL UP*/
					drive-strength = <2>; /* 2 MA */
				};
			};

			fsync2_default: fsync2_default {
				mux {
					/* CLK, DATA */
					pins = "gpio65";
					function = "cci_timer2";
				};

				config {
					pins = "gpio65";
					bias-pull-up; /* PULL UP*/
					drive-strength = <2>; /* 2 MA */
				};
			};
		};

		apps_smmu: iommu@15000000 {
			compatible = "qcom,sa7255p-smmu-500", "qcom,smmu-500", "arm,mmu-500";
			reg = <0x0 0x15000000 0x0 0x100000>;
			#iommu-cells = <2>;
			#global-interrupts = <2>;

			interrupts = <GIC_SPI 119 IRQ_TYPE_LEVEL_HIGH>,
				     <GIC_SPI 120 IRQ_TYPE_LEVEL_HIGH>,
				     <GIC_SPI  98 IRQ_TYPE_LEVEL_HIGH>,
				     <GIC_SPI  99 IRQ_TYPE_LEVEL_HIGH>,
				     <GIC_SPI 100 IRQ_TYPE_LEVEL_HIGH>,
				     <GIC_SPI 101 IRQ_TYPE_LEVEL_HIGH>,
				     <GIC_SPI 102 IRQ_TYPE_LEVEL_HIGH>,
				     <GIC_SPI 103 IRQ_TYPE_LEVEL_HIGH>,
				     <GIC_SPI 104 IRQ_TYPE_LEVEL_HIGH>,
				     <GIC_SPI 105 IRQ_TYPE_LEVEL_HIGH>,
				     <GIC_SPI 106 IRQ_TYPE_LEVEL_HIGH>,
				     <GIC_SPI 107 IRQ_TYPE_LEVEL_HIGH>,
				     <GIC_SPI 108 IRQ_TYPE_LEVEL_HIGH>,
				     <GIC_SPI 109 IRQ_TYPE_LEVEL_HIGH>,
				     <GIC_SPI 110 IRQ_TYPE_LEVEL_HIGH>,
				     <GIC_SPI 111 IRQ_TYPE_LEVEL_HIGH>,
				     <GIC_SPI 112 IRQ_TYPE_LEVEL_HIGH>,
				     <GIC_SPI 113 IRQ_TYPE_LEVEL_HIGH>,
				     <GIC_SPI 114 IRQ_TYPE_LEVEL_HIGH>,
				     <GIC_SPI 115 IRQ_TYPE_LEVEL_HIGH>,
				     <GIC_SPI 116 IRQ_TYPE_LEVEL_HIGH>,
				     <GIC_SPI 117 IRQ_TYPE_LEVEL_HIGH>,
				     <GIC_SPI 118 IRQ_TYPE_LEVEL_HIGH>,
				     <GIC_SPI 181 IRQ_TYPE_LEVEL_HIGH>,
				     <GIC_SPI 182 IRQ_TYPE_LEVEL_HIGH>,
				     <GIC_SPI 183 IRQ_TYPE_LEVEL_HIGH>,
				     <GIC_SPI 184 IRQ_TYPE_LEVEL_HIGH>,
				     <GIC_SPI 185 IRQ_TYPE_LEVEL_HIGH>,
				     <GIC_SPI 186 IRQ_TYPE_LEVEL_HIGH>,
				     <GIC_SPI 187 IRQ_TYPE_LEVEL_HIGH>,
				     <GIC_SPI 188 IRQ_TYPE_LEVEL_HIGH>,
				     <GIC_SPI 189 IRQ_TYPE_LEVEL_HIGH>,
				     <GIC_SPI 190 IRQ_TYPE_LEVEL_HIGH>,
				     <GIC_SPI 191 IRQ_TYPE_LEVEL_HIGH>,
				     <GIC_SPI 192 IRQ_TYPE_LEVEL_HIGH>,
				     <GIC_SPI 315 IRQ_TYPE_LEVEL_HIGH>,
				     <GIC_SPI 316 IRQ_TYPE_LEVEL_HIGH>,
				     <GIC_SPI 317 IRQ_TYPE_LEVEL_HIGH>,
				     <GIC_SPI 318 IRQ_TYPE_LEVEL_HIGH>,
				     <GIC_SPI 319 IRQ_TYPE_LEVEL_HIGH>,
				     <GIC_SPI 320 IRQ_TYPE_LEVEL_HIGH>,
				     <GIC_SPI 321 IRQ_TYPE_LEVEL_HIGH>,
				     <GIC_SPI 322 IRQ_TYPE_LEVEL_HIGH>,
				     <GIC_SPI 323 IRQ_TYPE_LEVEL_HIGH>,
				     <GIC_SPI 324 IRQ_TYPE_LEVEL_HIGH>,
				     <GIC_SPI 325 IRQ_TYPE_LEVEL_HIGH>,
				     <GIC_SPI 326 IRQ_TYPE_LEVEL_HIGH>,
				     <GIC_SPI 327 IRQ_TYPE_LEVEL_HIGH>,
				     <GIC_SPI 328 IRQ_TYPE_LEVEL_HIGH>,
				     <GIC_SPI 329 IRQ_TYPE_LEVEL_HIGH>,
				     <GIC_SPI 330 IRQ_TYPE_LEVEL_HIGH>,
				     <GIC_SPI 331 IRQ_TYPE_LEVEL_HIGH>,
				     <GIC_SPI 332 IRQ_TYPE_LEVEL_HIGH>,
				     <GIC_SPI 333 IRQ_TYPE_LEVEL_HIGH>,
				     <GIC_SPI 334 IRQ_TYPE_LEVEL_HIGH>,
				     <GIC_SPI 335 IRQ_TYPE_LEVEL_HIGH>,
				     <GIC_SPI 336 IRQ_TYPE_LEVEL_HIGH>,
				     <GIC_SPI 337 IRQ_TYPE_LEVEL_HIGH>,
				     <GIC_SPI 338 IRQ_TYPE_LEVEL_HIGH>,
				     <GIC_SPI 339 IRQ_TYPE_LEVEL_HIGH>,
				     <GIC_SPI 340 IRQ_TYPE_LEVEL_HIGH>,
				     <GIC_SPI 341 IRQ_TYPE_LEVEL_HIGH>,
				     <GIC_SPI 342 IRQ_TYPE_LEVEL_HIGH>,
				     <GIC_SPI 343 IRQ_TYPE_LEVEL_HIGH>,
				     <GIC_SPI 344 IRQ_TYPE_LEVEL_HIGH>,
				     <GIC_SPI 345 IRQ_TYPE_LEVEL_HIGH>,
				     <GIC_SPI 395 IRQ_TYPE_LEVEL_HIGH>,
				     <GIC_SPI 396 IRQ_TYPE_LEVEL_HIGH>,
				     <GIC_SPI 397 IRQ_TYPE_LEVEL_HIGH>,
				     <GIC_SPI 398 IRQ_TYPE_LEVEL_HIGH>,
				     <GIC_SPI 399 IRQ_TYPE_LEVEL_HIGH>,
				     <GIC_SPI 400 IRQ_TYPE_LEVEL_HIGH>,
				     <GIC_SPI 401 IRQ_TYPE_LEVEL_HIGH>,
				     <GIC_SPI 402 IRQ_TYPE_LEVEL_HIGH>,
				     <GIC_SPI 403 IRQ_TYPE_LEVEL_HIGH>,
				     <GIC_SPI 404 IRQ_TYPE_LEVEL_HIGH>,
				     <GIC_SPI 405 IRQ_TYPE_LEVEL_HIGH>,
				     <GIC_SPI 406 IRQ_TYPE_LEVEL_HIGH>,
				     <GIC_SPI 407 IRQ_TYPE_LEVEL_HIGH>,
				     <GIC_SPI 408 IRQ_TYPE_LEVEL_HIGH>,
				     <GIC_SPI 409 IRQ_TYPE_LEVEL_HIGH>,
				     <GIC_SPI 418 IRQ_TYPE_LEVEL_HIGH>,
				     <GIC_SPI 419 IRQ_TYPE_LEVEL_HIGH>,
				     <GIC_SPI 412 IRQ_TYPE_LEVEL_HIGH>,
				     <GIC_SPI 421 IRQ_TYPE_LEVEL_HIGH>,
				     <GIC_SPI 706 IRQ_TYPE_LEVEL_HIGH>,
				     <GIC_SPI 423 IRQ_TYPE_LEVEL_HIGH>,
				     <GIC_SPI 424 IRQ_TYPE_LEVEL_HIGH>,
				     <GIC_SPI 425 IRQ_TYPE_LEVEL_HIGH>,
				     <GIC_SPI 689 IRQ_TYPE_LEVEL_HIGH>,
				     <GIC_SPI 690 IRQ_TYPE_LEVEL_HIGH>,
				     <GIC_SPI 691 IRQ_TYPE_LEVEL_HIGH>,
				     <GIC_SPI 692 IRQ_TYPE_LEVEL_HIGH>,
				     <GIC_SPI 693 IRQ_TYPE_LEVEL_HIGH>,
				     <GIC_SPI 694 IRQ_TYPE_LEVEL_HIGH>,
				     <GIC_SPI 695 IRQ_TYPE_LEVEL_HIGH>,
				     <GIC_SPI 696 IRQ_TYPE_LEVEL_HIGH>,
				     <GIC_SPI 410 IRQ_TYPE_LEVEL_HIGH>,
				     <GIC_SPI 411 IRQ_TYPE_LEVEL_HIGH>,
				     <GIC_SPI 420 IRQ_TYPE_LEVEL_HIGH>,
				     <GIC_SPI 413 IRQ_TYPE_LEVEL_HIGH>,
				     <GIC_SPI 422 IRQ_TYPE_LEVEL_HIGH>,
				     <GIC_SPI 707 IRQ_TYPE_LEVEL_HIGH>,
				     <GIC_SPI 708 IRQ_TYPE_LEVEL_HIGH>,
				     <GIC_SPI 709 IRQ_TYPE_LEVEL_HIGH>,
				     <GIC_SPI 710 IRQ_TYPE_LEVEL_HIGH>,
				     <GIC_SPI 711 IRQ_TYPE_LEVEL_HIGH>,
				     <GIC_SPI 414 IRQ_TYPE_LEVEL_HIGH>,
				     <GIC_SPI 712 IRQ_TYPE_LEVEL_HIGH>,
				     <GIC_SPI 713 IRQ_TYPE_LEVEL_HIGH>,
				     <GIC_SPI 714 IRQ_TYPE_LEVEL_HIGH>,
				     <GIC_SPI 715 IRQ_TYPE_LEVEL_HIGH>,
				     <GIC_SPI 912 IRQ_TYPE_LEVEL_HIGH>,
				     <GIC_SPI 911 IRQ_TYPE_LEVEL_HIGH>,
				     <GIC_SPI 910 IRQ_TYPE_LEVEL_HIGH>,
				     <GIC_SPI 909 IRQ_TYPE_LEVEL_HIGH>,
				     <GIC_SPI 908 IRQ_TYPE_LEVEL_HIGH>,
				     <GIC_SPI 907 IRQ_TYPE_LEVEL_HIGH>,
				     <GIC_SPI 906 IRQ_TYPE_LEVEL_HIGH>,
				     <GIC_SPI 905 IRQ_TYPE_LEVEL_HIGH>,
				     <GIC_SPI 904 IRQ_TYPE_LEVEL_HIGH>,
				     <GIC_SPI 903 IRQ_TYPE_LEVEL_HIGH>,
				     <GIC_SPI 902 IRQ_TYPE_LEVEL_HIGH>,
				     <GIC_SPI 901 IRQ_TYPE_LEVEL_HIGH>,
				     <GIC_SPI 900 IRQ_TYPE_LEVEL_HIGH>,
				     <GIC_SPI 899 IRQ_TYPE_LEVEL_HIGH>,
				     <GIC_SPI 898 IRQ_TYPE_LEVEL_HIGH>,
				     <GIC_SPI 897 IRQ_TYPE_LEVEL_HIGH>,
				     <GIC_SPI 896 IRQ_TYPE_LEVEL_HIGH>,
				     <GIC_SPI 895 IRQ_TYPE_LEVEL_HIGH>;
		};

		pcie_smmu: iommu@15200000 {
			compatible = "qcom,sa7255p-smmu-500", "qcom,smmu-500", "arm,mmu-500";
			reg = <0x0 0x15200000 0x0 0x80000>;
			#iommu-cells = <2>;
			#global-interrupts = <2>;

			interrupts = <GIC_SPI 920 IRQ_TYPE_LEVEL_HIGH>,
				     <GIC_SPI 921 IRQ_TYPE_LEVEL_HIGH>,
				     <GIC_SPI 925 IRQ_TYPE_LEVEL_HIGH>,
				     <GIC_SPI 926 IRQ_TYPE_LEVEL_HIGH>,
				     <GIC_SPI 927 IRQ_TYPE_LEVEL_HIGH>,
				     <GIC_SPI 928 IRQ_TYPE_LEVEL_HIGH>,
				     <GIC_SPI 950 IRQ_TYPE_LEVEL_HIGH>,
				     <GIC_SPI 951 IRQ_TYPE_LEVEL_HIGH>,
				     <GIC_SPI 952 IRQ_TYPE_LEVEL_HIGH>,
				     <GIC_SPI 953 IRQ_TYPE_LEVEL_HIGH>,
				     <GIC_SPI 954 IRQ_TYPE_LEVEL_HIGH>,
				     <GIC_SPI 955 IRQ_TYPE_LEVEL_HIGH>,
				     <GIC_SPI 956 IRQ_TYPE_LEVEL_HIGH>,
				     <GIC_SPI 957 IRQ_TYPE_LEVEL_HIGH>,
				     <GIC_SPI 958 IRQ_TYPE_LEVEL_HIGH>,
				     <GIC_SPI 885 IRQ_TYPE_LEVEL_HIGH>,
				     <GIC_SPI 886 IRQ_TYPE_LEVEL_HIGH>,
				     <GIC_SPI 887 IRQ_TYPE_LEVEL_HIGH>,
				     <GIC_SPI 888 IRQ_TYPE_LEVEL_HIGH>,
				     <GIC_SPI 820 IRQ_TYPE_LEVEL_HIGH>,
				     <GIC_SPI 822 IRQ_TYPE_LEVEL_HIGH>,
				     <GIC_SPI 823 IRQ_TYPE_LEVEL_HIGH>,
				     <GIC_SPI 310 IRQ_TYPE_LEVEL_HIGH>,
				     <GIC_SPI 446 IRQ_TYPE_LEVEL_HIGH>,
				     <GIC_SPI 447 IRQ_TYPE_LEVEL_HIGH>,
				     <GIC_SPI 452 IRQ_TYPE_LEVEL_HIGH>,
				     <GIC_SPI 840 IRQ_TYPE_LEVEL_HIGH>,
				     <GIC_SPI 841 IRQ_TYPE_LEVEL_HIGH>,
				     <GIC_SPI 842 IRQ_TYPE_LEVEL_HIGH>,
				     <GIC_SPI 843 IRQ_TYPE_LEVEL_HIGH>,
				     <GIC_SPI 844 IRQ_TYPE_LEVEL_HIGH>,
				     <GIC_SPI 845 IRQ_TYPE_LEVEL_HIGH>,
				     <GIC_SPI 846 IRQ_TYPE_LEVEL_HIGH>,
				     <GIC_SPI 847 IRQ_TYPE_LEVEL_HIGH>,
				     <GIC_SPI 848 IRQ_TYPE_LEVEL_HIGH>,
				     <GIC_SPI 849 IRQ_TYPE_LEVEL_HIGH>,
				     <GIC_SPI 802 IRQ_TYPE_LEVEL_HIGH>,
				     <GIC_SPI 803 IRQ_TYPE_LEVEL_HIGH>,
				     <GIC_SPI 804 IRQ_TYPE_LEVEL_HIGH>,
				     <GIC_SPI 805 IRQ_TYPE_LEVEL_HIGH>,
				     <GIC_SPI 806 IRQ_TYPE_LEVEL_HIGH>,
				     <GIC_SPI 807 IRQ_TYPE_LEVEL_HIGH>,
				     <GIC_SPI 808 IRQ_TYPE_LEVEL_HIGH>,
				     <GIC_SPI 809 IRQ_TYPE_LEVEL_HIGH>,
				     <GIC_SPI 810 IRQ_TYPE_LEVEL_HIGH>,
				     <GIC_SPI 811 IRQ_TYPE_LEVEL_HIGH>,
				     <GIC_SPI 812 IRQ_TYPE_LEVEL_HIGH>,
				     <GIC_SPI 813 IRQ_TYPE_LEVEL_HIGH>,
				     <GIC_SPI 814 IRQ_TYPE_LEVEL_HIGH>,
				     <GIC_SPI 836 IRQ_TYPE_LEVEL_HIGH>,
				     <GIC_SPI 837 IRQ_TYPE_LEVEL_HIGH>,
				     <GIC_SPI 838 IRQ_TYPE_LEVEL_HIGH>,
				     <GIC_SPI 839 IRQ_TYPE_LEVEL_HIGH>,
				     <GIC_SPI 854 IRQ_TYPE_LEVEL_HIGH>,
				     <GIC_SPI 855 IRQ_TYPE_LEVEL_HIGH>,
				     <GIC_SPI 856 IRQ_TYPE_LEVEL_HIGH>,
				     <GIC_SPI 790 IRQ_TYPE_LEVEL_HIGH>,
				     <GIC_SPI 791 IRQ_TYPE_LEVEL_HIGH>,
				     <GIC_SPI 792 IRQ_TYPE_LEVEL_HIGH>,
				     <GIC_SPI 793 IRQ_TYPE_LEVEL_HIGH>,
				     <GIC_SPI 794 IRQ_TYPE_LEVEL_HIGH>,
				     <GIC_SPI 795 IRQ_TYPE_LEVEL_HIGH>,
				     <GIC_SPI 796 IRQ_TYPE_LEVEL_HIGH>,
				     <GIC_SPI 639 IRQ_TYPE_LEVEL_HIGH>,
				     <GIC_SPI 79 IRQ_TYPE_LEVEL_HIGH>,
				     <GIC_SPI 640 IRQ_TYPE_LEVEL_HIGH>;
		};

		adreno_smmu: iommu@3da0000 {
			compatible = "qcom,sa7255p-smmu-500", "qcom,adreno-smmu",
					"qcom,smmu-500", "arm,mmu-500";
			reg = <0x0 0x3da0000 0x0 0x20000>;
			#iommu-cells = <2>;
			#global-interrupts = <2>;
			dma-coherent;
			power-domains = <&gpucc GPU_CC_CX_GDSC>;
			clocks = <&gcc GCC_GPU_MEMNOC_GFX_CLK>,
				 <&gcc GCC_GPU_SNOC_DVM_GFX_CLK>,
				 <&gpucc GPU_CC_AHB_CLK>,
				 <&gpucc GPU_CC_HLOS1_VOTE_GPU_SMMU_CLK>,
				 <&gpucc GPU_CC_CX_GMU_CLK>,
				 <&gpucc GPU_CC_HUB_CX_INT_CLK>,
				 <&gpucc GPU_CC_HUB_AON_CLK>;
			clock-names = "gcc_gpu_memnoc_gfx_clk",
				      "gcc_gpu_snoc_dvm_gfx_clk",
				      "gpu_cc_ahb_clk",
				      "gpu_cc_hlos1_vote_gpu_smmu_clk",
				      "gpu_cc_cx_gmu_clk",
				      "gpu_cc_hub_cx_int_clk",
				      "gpu_cc_hub_aon_clk";
			interrupts = <GIC_SPI 672 IRQ_TYPE_LEVEL_HIGH>,
				     <GIC_SPI 673 IRQ_TYPE_LEVEL_HIGH>,
				     <GIC_SPI 678 IRQ_TYPE_LEVEL_HIGH>,
				     <GIC_SPI 679 IRQ_TYPE_LEVEL_HIGH>,
				     <GIC_SPI 680 IRQ_TYPE_LEVEL_HIGH>,
				     <GIC_SPI 681 IRQ_TYPE_LEVEL_HIGH>,
				     <GIC_SPI 682 IRQ_TYPE_LEVEL_HIGH>,
				     <GIC_SPI 683 IRQ_TYPE_LEVEL_HIGH>,
				     <GIC_SPI 684 IRQ_TYPE_LEVEL_HIGH>,
				     <GIC_SPI 685 IRQ_TYPE_LEVEL_HIGH>,
				     <GIC_SPI 686 IRQ_TYPE_LEVEL_HIGH>,
				     <GIC_SPI 687 IRQ_TYPE_LEVEL_HIGH>;
		};

		watchdog@17c10000 {
			compatible = "qcom,kpss-wdt";
			reg = <0x0 0x17c10000 0x0 0x1000>;
			clocks = <&sleep_clk>;
			interrupts = <GIC_SPI 0 IRQ_TYPE_EDGE_RISING>;
		};

		tcsr: syscon@1fc0000 {
		       compatible = "syscon";
		       reg = <0x0 0x1fc0000 0x0 0x30000>;
		};

		ipcc0: mailbox@408000 {
			compatible = "qcom,sa7255p-ipcc", "qcom,ipcc";
			reg = <0x0 0x00408000 0x0 0x1000>;
			interrupts = <GIC_SPI 229 IRQ_TYPE_LEVEL_HIGH>;
			interrupt-controller;
			#interrupt-cells = <3>;
			#mbox-cells = <2>;
		};

		ipcc1: mailbox@488000 {
			compatible = "qcom,sa7255p-ipcc", "qcom,ipcc";
			reg = <0x0 0x488000 0x0 0x1000>;
			interrupts = <GIC_SPI 231 IRQ_TYPE_LEVEL_HIGH>;
			interrupt-controller;
			#interrupt-cells = <3>;
			#mbox-cells = <2>;
		};

		ethernet0: ethernet@23040000 {
			compatible = "qcom,sa7255p-ethqos";
			reg = <0x0 0x23040000 0x0 0x10000>,
				<0x0 0x23056000 0x0 0x100>;
			reg-names = "stmmaceth", "rgmii";

			interrupts = <GIC_SPI 946 IRQ_TYPE_LEVEL_HIGH>,
				<GIC_SPI 783 IRQ_TYPE_LEVEL_HIGH>;
			interrupt-names = "macirq", "sfty";

			clocks = <&gcc GCC_EMAC0_AXI_CLK>,
				 <&gcc GCC_EMAC0_SLV_AHB_CLK>,
				 <&gcc GCC_EMAC0_PTP_CLK>,
				 <&gcc GCC_EMAC0_PHY_AUX_CLK>;
			clock-names = "stmmaceth",
				"pclk",
				"ptp_ref",
				"phyaux";
			power-domains = <&gcc EMAC0_GDSC>;

			phys = <&serdes0>;
			phy-names = "serdes";

			iommus = <&apps_smmu 0x120 0xf>;
			dma-coherent;

			snps,tso;
			snps,pbl = <32>;
			rx-fifo-depth = <16384>;
			tx-fifo-depth = <20480>;

			status = "disabled";
		};

		qfprom_pte: qfprom@780158 {
			compatible = "qcom,qfprom";
			reg = <0x0 0x00780158 0x0 0x4>;
			#address-cells = <2>;
			#size-cells = <2>;
		};

		qfprom_tcsr: qfprom@1FFF018 {
			compatible = "qcom,qfprom";
			reg = <0x0 0x1FFF018 0x0 0x4>;
			#address-cells = <2>;
			#size-cells = <2>;
		};
	};

	kaslr_store {
		compatible = "qcom,kaslr-off-store";
		reg = <0x0 0x146d86d0 0x0 0xc>;
	};

	mini_dump_mode {
		compatible = "qcom,minidump";
	};

	mem_dump {
		compatible = "qcom,mem-dump";
		memory-region = <&dump_mem>;

		c0_context {
			qcom,dump-size = <0x800>;
			qcom,dump-id = <0x0>;
		};

		c100_context {
			qcom,dump-size = <0x800>;
			qcom,dump-id = <0x1>;
		};

		c200_context {
			qcom,dump-size = <0x800>;
			qcom,dump-id = <0x2>;
		};

		c300_context {
			qcom,dump-size = <0x800>;
			qcom,dump-id = <0x3>;
		};

		c400_context {
			qcom,dump-size = <0x800>;
			qcom,dump-id = <0x4>;
		};

		c500_context {
			qcom,dump-size = <0x800>;
			qcom,dump-id = <0x5>;
		};

		c600_context {
			qcom,dump-size = <0x800>;
			qcom,dump-id = <0x6>;
		};

		c700_context {
			qcom,dump-size = <0x800>;
			qcom,dump-id = <0x7>;
		};

		c0_scandump: c0_scandump {
			qcom,dump-size = <0x40000>;
			qcom,dump-id = <0x130>;
		};

		c100_scandump: c100_scandump {
			qcom,dump-size = <0x40000>;
			qcom,dump-id = <0x131>;
		};

		c200_scandump: c200_scandump {
			qcom,dump-size = <0x40000>;
			qcom,dump-id = <0x132>;
		};

		c300_scandump: c300_scandump {
			qcom,dump-size = <0x40000>;
			qcom,dump-id = <0x133>;
		};

		c10000_scandump: c10000_scandump {
			qcom,dump-size = <0x40000>;
			qcom,dump-id = <0x134>;
		};

		c10100_scandump: c10100_scandump {
			qcom,dump-size = <0x40000>;
			qcom,dump-id = <0x135>;
		};

		c10200_scandump: c10200_scandump {
			qcom,dump-size = <0x40000>;
			qcom,dump-id = <0x136>;
		};

		c10300_scandump: c10300_scandump {
			qcom,dump-size = <0x40000>;
			qcom,dump-id = <0x137>;
		};

		cpuss_reg: cpuss_reg {
			qcom,dump-size = <0x20000>;
			qcom,dump-id = <0xef>;
		};

		etf_reg {
			qcom,dump-size = <0x1000>;
			qcom,dump-id = <0x101>;
		};

		etf_swao {
			qcom,dump-size = <0x8400>;
			qcom,dump-id = <0xf1>;
		};

		etfswao_reg {
			qcom,dump-size = <0x1000>;
			qcom,dump-id = <0x102>;
		};

		etr_reg {
			qcom,dump-size = <0x1000>;
			qcom,dump-id = <0x100>;
		};

		fcm {
			qcom,dump-size = <0x8400>;
			qcom,dump-id = <0xee>;
		};

		l1_dcache0 {
			qcom,dump-size = <0x12100>;
			qcom,dump-id = <0x80>;
		};

		l1_dcache100 {
			qcom,dump-size = <0x12100>;
			qcom,dump-id = <0x81>;
		};

		l1_dcache200 {
			qcom,dump-size = <0x12100>;
			qcom,dump-id = <0x82>;
		};

		l1_dcache300 {
			qcom,dump-size = <0x12100>;
			qcom,dump-id = <0x83>;
		};

		l1_dcache10000 {
			qcom,dump-size = <0x12100>;
			qcom,dump-id = <0x84>;
		};

		l1_dcache10100 {
			qcom,dump-size = <0x12100>;
			qcom,dump-id = <0x85>;
		};

		l1_dcache10200 {
			qcom,dump-size = <0x12100>;
			qcom,dump-id = <0x86>;
		};

		l1_dcache10300 {
			qcom,dump-size = <0x12100>;
			qcom,dump-id = <0x87>;
		};

		l1_dtlb10000 {
			qcom,dump-size = <0x300>;
			qcom,dump-id = <0x44>;
		};

		l1_dtlb10100 {
			qcom,dump-size = <0x300>;
			qcom,dump-id = <0x45>;
		};

		l1_dtlb10200 {
			qcom,dump-size = <0x300>;
			qcom,dump-id = <0x46>;
		};

		l1_dtlb10300 {
			qcom,dump-size = <0x300>;
			qcom,dump-id = <0x47>;
		};

		l1_icache0 {
			qcom,dump-size = <0x26100>;
			qcom,dump-id = <0x60>;
		};

		l1_icache100 {
			qcom,dump-size = <0x26100>;
			qcom,dump-id = <0x61>;
		};

		l1_icache200 {
			qcom,dump-size = <0x26100>;
			qcom,dump-id = <0x62>;
		};

		l1_icache300 {
			qcom,dump-size = <0x26100>;
			qcom,dump-id = <0x63>;
		};

		l1_icache10000 {
			qcom,dump-size = <0x26100>;
			qcom,dump-id = <0x64>;
		};

		l1_icache10100 {
			qcom,dump-size = <0x26100>;
			qcom,dump-id = <0x65>;
		};

		l1_icache10200 {
			qcom,dump-size = <0x26100>;
			qcom,dump-id = <0x66>;
		};

		l1_icache10300 {
			qcom,dump-size = <0x26100>;
			qcom,dump-id = <0x67>;
		};

		l1_itlb10000 {
			qcom,dump-size = <0x300>;
			qcom,dump-id = <0x24>;
		};

		l1_itlb10100 {
			qcom,dump-size = <0x300>;
			qcom,dump-id = <0x25>;
		};

		l1_itlb10200 {
			qcom,dump-size = <0x300>;
			qcom,dump-id = <0x26>;
		};

		l1_itlb10300 {
			qcom,dump-size = <0x300>;
			qcom,dump-id = <0x27>;
		};

		l2_cache10000 {
			qcom,dump-size = <0x90100>;
			qcom,dump-id = <0xc4>;
		};

		l2_cache10100 {
			qcom,dump-size = <0x90100>;
			qcom,dump-id = <0xc5>;
		};

		l2_cache10200 {
			qcom,dump-size = <0x90100>;
			qcom,dump-id = <0xc6>;
		};

		l2_cache10300 {
			qcom,dump-size = <0x90100>;
			qcom,dump-id = <0xc7>;
		};

		l2_tlb0 {
			qcom,dump-size = <0x6100>;
			qcom,dump-id = <0x120>;
		};

		l2_tlb100 {
			qcom,dump-size = <0x6100>;
			qcom,dump-id = <0x121>;
		};

		l2_tlb200 {
			qcom,dump-size = <0x6100>;
			qcom,dump-id = <0x122>;
		};

		l2_tlb300 {
			qcom,dump-size = <0x6100>;
			qcom,dump-id = <0x123>;
		};

		l2_tlb10000 {
			qcom,dump-size = <0x6100>;
			qcom,dump-id = <0x124>;
		};

		l2_tlb10100 {
			qcom,dump-size = <0x6100>;
			qcom,dump-id = <0x125>;
		};

		l2_tlb10200 {
			qcom,dump-size = <0x6100>;
			qcom,dump-id = <0x126>;
		};

		l2_tlb10300 {
			qcom,dump-size = <0x6100>;
			qcom,dump-id = <0x127>;
		};

		misc_data {
			qcom,dump-size = <0x1000>;
			qcom,dump-id = <0xe8>;
		};

		pmic {
			qcom,dump-size = <0x80000>;
			qcom,dump-id = <0xe4>;
		};

		rpmh {
			qcom,dump-size = <0x2000000>;
			qcom,dump-id = <0xec>;
		};

		rpm_sw {
			qcom,dump-size = <0x28000>;
			qcom,dump-id = <0xea>;
		};

		tmc_etf {
			qcom,dump-size = <0x10000>;
			qcom,dump-id = <0xf0>;
		};
	};

	kryo_erp: erp {
		compatible = "arm,arm64-kryo-cpu-erp";
		interrupts = <GIC_PPI 0 IRQ_TYPE_LEVEL_LOW>,
				<GIC_SPI 36 IRQ_TYPE_LEVEL_HIGH>,
				<GIC_SPI 21 IRQ_TYPE_LEVEL_HIGH>;
		interrupt-names = "l1-l2-faultirq",
					"l3-c0-scu-faultirq",
					"l3-c1-scu-faultirq";
	};

	dload_mode {
		compatible = "qcom,dload-mode";
	};
};

